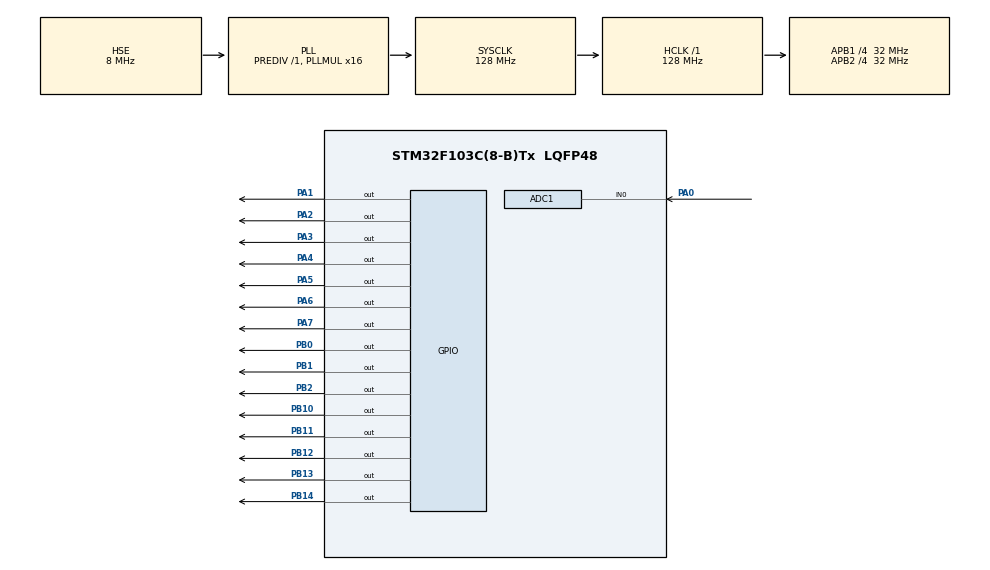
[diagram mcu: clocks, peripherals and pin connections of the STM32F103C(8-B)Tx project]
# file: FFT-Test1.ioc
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ADC1.Channel-7\#ChannelRegularConversion=ADC_CHANNEL_0
ADC1.ContinuousConvMode=DISABLE
ADC1.DataAlign=ADC_DATAALIGN_RIGHT
ADC1.DiscontinuousConvMode=DISABLE
ADC1.EnableAnalogWatchDog=false
ADC1.EnableRegularConversion=ENABLE
ADC1.ExternalTrigConv=ADC_SOFTWARE_START
ADC1.InjNumberOfConversion=0
ADC1.NbrOfConversion=1
ADC1.NbrOfConversionFlag=1
ADC1.Rank-7\#ChannelRegularConversion=1
ADC1.SamplingTime-7\#ChannelRegularConversion=ADC_SAMPLETIME_1CYCLE_5
ADC1.ScanConvMode=ADC_SCAN_DISABLE
ADC1.master=1
Mcu.Family=STM32F1
Mcu.Name=STM32F103C(8-B)Tx
Mcu.Package=LQFP48
NVIC.PriorityGroup=NVIC_PRIORITYGROUP_4
NVIC.TIM2_IRQn=true\:0\:0\:true\:false\:true\:true
NVIC.TIM4_IRQn=true\:1\:0\:true\:false\:true\:true
PA0-WKUP.Signal=ADCx_IN0
PA1.GPIO_ModeDefaultOutputPP=GPIO_MODE_OUTPUT_PP
PA1.GPIO_Speed=GPIO_SPEED_FREQ_HIGH
PA1.PinState=GPIO_PIN_SET
PA1.Signal=GPIO_Output
PA13.Mode=Serial_Wire
PA13.Signal=SYS_JTMS-SWDIO
PA14.Mode=Serial_Wire
PA14.Signal=SYS_JTCK-SWCLK
PA2.GPIO_ModeDefaultOutputPP=GPIO_MODE_OUTPUT_PP
PA2.GPIO_Speed=GPIO_SPEED_FREQ_HIGH
PA2.PinState=GPIO_PIN_SET
PA2.Signal=GPIO_Output
PA3.GPIO_ModeDefaultOutputPP=GPIO_MODE_OUTPUT_PP
PA3.GPIO_Speed=GPIO_SPEED_FREQ_HIGH
PA3.PinState=GPIO_PIN_SET
PA3.Signal=GPIO_Output
PA4.GPIO_ModeDefaultOutputPP=GPIO_MODE_OUTPUT_PP
PA4.GPIO_Speed=GPIO_SPEED_FREQ_HIGH
PA4.PinState=GPIO_PIN_SET
PA4.Signal=GPIO_Output
PA5.GPIO_ModeDefaultOutputPP=GPIO_MODE_OUTPUT_PP
PA5.GPIO_Speed=GPIO_SPEED_FREQ_HIGH
PA5.PinState=GPIO_PIN_SET
PA5.Signal=GPIO_Output
PA6.GPIO_ModeDefaultOutputPP=GPIO_MODE_OUTPUT_PP
PA6.GPIO_Speed=GPIO_SPEED_FREQ_HIGH
PA6.PinState=GPIO_PIN_SET
PA6.Signal=GPIO_Output
PA7.GPIO_ModeDefaultOutputPP=GPIO_MODE_OUTPUT_PP
PA7.GPIO_Speed=GPIO_SPEED_FREQ_HIGH
PA7.PinState=GPIO_PIN_SET
PA7.Signal=GPIO_Output
PB0.GPIO_ModeDefaultOutputPP=GPIO_MODE_OUTPUT_PP
PB0.GPIO_Speed=GPIO_SPEED_FREQ_HIGH
PB0.PinState=GPIO_PIN_SET
PB0.Signal=GPIO_Output
PB1.GPIO_ModeDefaultOutputPP=GPIO_MODE_OUTPUT_PP
PB1.GPIO_Speed=GPIO_SPEED_FREQ_HIGH
PB1.PinState=GPIO_PIN_SET
PB1.Signal=GPIO_Output
PB10.GPIO_ModeDefaultOutputPP=GPIO_MODE_OUTPUT_PP
PB10.GPIO_Speed=GPIO_SPEED_FREQ_HIGH
PB10.PinState=GPIO_PIN_SET
PB10.Signal=GPIO_Output
PB11.GPIO_Speed=GPIO_SPEED_FREQ_HIGH
PB11.PinState=GPIO_PIN_SET
PB11.Signal=GPIO_Output
PB12.GPIO_ModeDefaultOutputPP=GPIO_MODE_OUTPUT_PP
PB12.GPIO_Speed=GPIO_SPEED_FREQ_HIGH
PB12.PinState=GPIO_PIN_SET
PB12.Signal=GPIO_Output
PB13.GPIO_ModeDefaultOutputPP=GPIO_MODE_OUTPUT_PP
PB13.GPIO_Speed=GPIO_SPEED_FREQ_HIGH
PB13.PinState=GPIO_PIN_SET
PB13.Signal=GPIO_Output
PB14.GPIO_ModeDefaultOutputPP=GPIO_MODE_OUTPUT_PP
PB14.GPIO_Speed=GPIO_SPEED_FREQ_HIGH
PB14.PinState=GPIO_PIN_SET
PB14.Signal=GPIO_Output
PB2.GPIO_ModeDefaultOutputPP=GPIO_MODE_OUTPUT_PP
PB2.GPIO_Speed=GPIO_SPEED_FREQ_HIGH
PB2.PinState=GPIO_PIN_SET
PB2.Signal=GPIO_Output
PD0-OSC_IN.Mode=HSE-External-Oscillator
PD0-OSC_IN.Signal=RCC_OSC_IN
PD1-OSC_OUT.Mode=HSE-External-Oscillator
PD1-OSC_OUT.Signal=RCC_OSC_OUT
ProjectManager.HeapSize=0x200
ProjectManager.StackSize=0x400
ProjectManager.TargetToolchain=MDK-ARM V5
RCC.ADCPresc=RCC_ADCPCLK2_DIV4
RCC.AHBFreq_Value=128000000
RCC.APB1CLKDivider=RCC_HCLK_DIV4
RCC.APB1Freq_Value=32000000
RCC.APB1TimFreq_Value=64000000
RCC.APB2CLKDivider=RCC_HCLK_DIV4
RCC.APB2Freq_Value=32000000
RCC.APB2TimFreq_Value=64000000
RCC.HCLKFreq_Value=128000000
RCC.PLLMUL=RCC_PLL_MUL16
RCC.PLLSourceVirtual=RCC_PLLSOURCE_HSE
RCC.SYSCLKFreq_VALUE=128000000
RCC.SYSCLKSource=RCC_SYSCLKSOURCE_PLLCLK
RCC.USBFreq_Value=85333333.33333333
RCC.USBPrescaler=RCC_USBCLKSOURCE_PLL_DIV1_5
SH.ADCx_IN0.0=ADC1_IN0,IN0
TIM2.Period=1999
TIM2.Prescaler=32000
TIM3.Period=24
TIM3.Prescaler=64
TIM4.Period=33
TIM4.Prescaler=1152
VP_TIM2_VS_ClockSourceINT.Mode=Internal
VP_TIM3_VS_ClockSourceINT.Mode=Internal
VP_TIM4_VS_ClockSourceINT.Mode=Internal
board=FFT-Test1

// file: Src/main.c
#include "main.h"
#include "stm32f1xx_hal.h"

/* USER CODE BEGIN Includes */
#include <stdlib.h>
#include <math.h>
/* USER CODE END Includes */

ADC_HandleTypeDef hadc1;

TIM_HandleTypeDef htim2;
TIM_HandleTypeDef htim3;
TIM_HandleTypeDef htim4;

/* USER CODE BEGIN PV */
/* Private variables ---------------------------------------------------------*/

#define xuat      10 //B
#define OE        11 //B
#define clk       1  //A

#define A         0  //B
#define B         1  //B
#define C         13 //B
#define D         14 //B

#define B2        7
#define R2        6
#define G2        2

#define B1        5
#define R1        4
#define G1        3

#define OE_P       GPIOB
#define xuat_P     GPIOB
#define clk_P      GPIOA
#define A_P        GPIOB
#define B_P        GPIOB
#define C_P        GPIOB
#define D_P        GPIOB

const unsigned int timer_clock[5]={9,18,36,72,144}; // he so chia T4
//const unsigned int timer_clock[5]={9,18,36,72,144,288,575,1152};
unsigned char vitri_bit=0,row=0; // kiem tra xem dang quet den bit nao

signed char hang_led;
unsigned char display[3][32][64]={0};
unsigned int dem_ADC;

uint32_t t_show;

/* USER CODE END PV */

void SystemClock_Config(void);
static void MX_GPIO_Init(void);
static void MX_TIM2_Init(void);
static void MX_ADC1_Init(void);
static void MX_TIM4_Init(void);
static void MX_TIM3_Init(void);

/* USER CODE BEGIN PFP */
/* Private function prototypes -----------------------------------------------*/

#define N       512
#define log2N   9

int32_t RE[N];
int32_t IM[N];
int32_t data_M[64];
char data_MT[64];

// bang tra cuu Sin(a) cho FFT 512 diem
const signed char Sin_table[511] =
{
0,    // Temp_N = 2
0,-100,    // Temp_N = 4
0,-71,-100,-71,    // Temp_N = 8
0,-38,-71,-92,-100,-92,-71,-38,    // Temp_N = 16
0,-20,-38,-56,-71,-83,-92,-98,-100,-98,-92,-83,-71,-56,-38,-20,    // Temp_N = 32
0,-10,-20,-29,-38,-47,-56,-63,-71,-77,-83,-88,-92,-96,-98,-100,-100,-100,-98,-96,-92,-88,-83,-77,-71,-63,-56,-47,-38,-29,-20,-10,    // Temp_N = 64
0,-5,-10,-15,-20,-24,-29,-34,-38,-43,-47,-51,-56,-60,-63,-67,-71,-74,-77,-80,-83,-86,-88,-90,-92,-94,-96,-97,-98,-99,-100,-100,-100,-100,-100,-99,-98,-97,-96,-94,-92,-90,-88,-86,-83,-80,-77,-74,-71,-67,-63,-60,-56,-51,-47,-43,-38,-34,-29,-24,-20,-15,-10,-5,    // Temp_N = 128
0,-3,-5,-7,-10,-12,-15,-17,-20,-22,-24,-27,-29,-31,-34,-36,-38,-41,-43,-45,-47,-49,-51,-54,-56,-58,-60,-62,-63,-65,-67,-69,-71,-72,-74,-76,-77,-79,-80,-82,-83,-85,-86,-87,-88,-89,-90,-91,-92,-93,-94,-95,-96,-96,-97,-98,-98,-99,-99,-99,-100,-100,-100,-100,-100,-100,-100,-100,-100,-99,-99,-99,-98,-98,-97,-96,-96,-95,-94,-93,-92,-91,-90,-89,-88,-87,-86,-85,-83,-82,-80,-79,-77,-76,-74,-72,-71,-69,-67,-65,-63,-62,-60,-58,-56,-54,-51,-49,-47,-45,-43,-41,-38,-36,-34,-31,-29,-27,-24,-22,-20,-17,-15,-12,-10,-7,-5,-3,    // Temp_N = 256
0,-1,-3,-4,-5,-6,-7,-9,-10,-11,-12,-14,-15,-16,-17,-18,-20,-21,-22,-23,-24,-26,-27,-28,-29,-30,-31,-33,-34,-35,-36,-37,-38,-39,-41,-42,-43,-44,-45,-46,-47,-48,-49,-50,-51,-53,-54,-55,-56,-57,-58,-59,-60,-61,-62,-63,-63,-64,-65,-66,-67,-68,-69,-70,-71,-72,-72,-73,-74,-75,-76,-77,-77,-78,-79,-80,-80,-81,-82,-83,-83,-84,-85,-85,-86,-86,-87,-88,-88,-89,-89,-90,-90,-91,-91,-92,-92,-93,-93,-94,-94,-95,-95,-95,-96,-96,-96,-97,-97,-97,-98,-98,-98,-98,-99,-99,-99,-99,-99,-99,-100,-100,-100,-100,-100,-100,-100,-100,-100,-100,-100,-100,-100,-100,-100,-100,-100,-99,-99,-99,-99,-99,-99,-98,-98,-98,-98,-97,-97,-97,-96,-96,-96,-95,-95,-95,-94,-94,-93,-93,-92,-92,-91,-91,-90,-90,-89,-89,-88,-88,-87,-86,-86,-85,-85,-84,-83,-83,-82,-81,-80,-80,-79,-78,-77,-77,-76,-75,-74,-73,-72,-72,-71,-70,-69,-68,-67,-66,-65,-64,-63,-63,-62,-61,-60,-59,-58,-57,-56,-55,-54,-53,-51,-50,-49,-48,-47,-46,-45,-44,-43,-42,-41,-39,-38,-37,-36,-35,-34,-33,-31,-30,-29,-28,-27,-26,-24,-23,-22,-21,-20,-18,-17,-16,-15,-14,-12,-11,-10,-9,-7,-6,-5,-4,-3,-1,    // Temp_N = 512
};

// bang tra cuu Cos(a) cho FFT 512 diem
const signed char Cos_table[511] =
{
100,    // Temp_N = 2
100,0,    // Temp_N = 4
100,71,0,-71,    // Temp_N = 8
100,92,71,38,0,-38,-71,-92,    // Temp_N = 16
100,98,92,83,71,56,38,20,0,-20,-38,-56,-71,-83,-92,-98,    // Temp_N = 32
100,100,98,96,92,88,83,77,71,63,56,47,38,29,20,10,0,-10,-20,-29,-38,-47,-56,-63,-71,-77,-83,-88,-92,-96,-98,-100,    // Temp_N = 64
100,100,100,99,98,97,96,94,92,90,88,86,83,80,77,74,71,67,63,60,56,51,47,43,38,34,29,24,20,15,10,5,0,-5,-10,-15,-20,-24,-29,-34,-38,-43,-47,-51,-56,-60,-63,-67,-71,-74,-77,-80,-83,-86,-88,-90,-92,-94,-96,-97,-98,-99,-100,-100,    // Temp_N = 128
100,100,100,100,100,99,99,99,98,98,97,96,96,95,94,93,92,91,90,89,88,87,86,85,83,82,80,79,77,76,74,72,71,69,67,65,63,62,60,58,56,54,51,49,47,45,43,41,38,36,34,31,29,27,24,22,20,17,15,12,10,7,5,3,0,-3,-5,-7,-10,-12,-15,-17,-20,-22,-24,-27,-29,-31,-34,-36,-38,-41,-43,-45,-47,-49,-51,-54,-56,-58,-60,-62,-63,-65,-67,-69,-71,-72,-74,-76,-77,-79,-80,-82,-83,-85,-86,-87,-88,-89,-90,-91,-92,-93,-94,-95,-96,-96,-97,-98,-98,-99,-99,-99,-100,-100,-100,-100,    // Temp_N = 256
100,100,100,100,100,100,100,100,100,99,99,99,99,99,99,98,98,98,98,97,97,97,96,96,96,95,95,95,94,94,93,93,92,92,91,91,90,90,89,89,88,88,87,86,86,85,85,84,83,83,82,81,80,80,79,78,77,77,76,75,74,73,72,72,71,70,69,68,67,66,65,64,63,63,62,61,60,59,58,57,56,55,54,53,51,50,49,48,47,46,45,44,43,42,41,39,38,37,36,35,34,33,31,30,29,28,27,26,24,23,22,21,20,18,17,16,15,14,12,11,10,9,7,6,5,4,3,1,0,-1,-3,-4,-5,-6,-7,-9,-10,-11,-12,-14,-15,-16,-17,-18,-20,-21,-22,-23,-24,-26,-27,-28,-29,-30,-31,-33,-34,-35,-36,-37,-38,-39,-41,-42,-43,-44,-45,-46,-47,-48,-49,-50,-51,-53,-54,-55,-56,-57,-58,-59,-60,-61,-62,-63,-63,-64,-65,-66,-67,-68,-69,-70,-71,-72,-72,-73,-74,-75,-76,-77,-77,-78,-79,-80,-80,-81,-82,-83,-83,-84,-85,-85,-86,-86,-87,-88,-88,-89,-89,-90,-90,-91,-91,-92,-92,-93,-93,-94,-94,-95,-95,-95,-96,-96,-96,-97,-97,-97,-98,-98,-98,-98,-99,-99,-99,-99,-99,-99,-100,-100,-100,-100,-100,-100,-100,-100,    // Temp_N = 512
};
const unsigned char image[3][32][64]=
{
//[64x32]  (C) 2017 By Dao Nguyen
//Red
0x03,0x01,0x00,0x00,0x00,0x00,0x00,0x00,0x00,0x01,0x01,0x00,0x00,0x00,0x00,0x00,0x00,0x00,0x00,0x00,0x00,0x00,0x00,0x00,0x00,0x00,0x02,0x04,0x06,0x09,0x0D,0x10,0x13,0x16,0x1A,0x1C,0x1E,0x1F,0x1F,0x1E,0x1E,0x1E,0x1F,0x1F,0x1F,0x1F,0x1F,0x1F,0x1F,0x1F,0x1F,0x1F,0x1F,0x1F,0x1F,0x1F,0x1F,0x1F,0x1F,0x1F,0x1F,0x1F,0x1F,0x1F,
0x04,0x02,0x00,0x00,0x00,0x00,0x00,0x00,0x00,0x00,0x00,0x00,0x00,0x00,0x00,0x00,0x00,0x00,0x00,0x00,0x00,0x00,0x00,0x00,0x00,0x00,0x02,0x03,0x05,0x08,0x0C,0x0F,0x12,0x15,0x19,0x1B,0x1D,0x1F,0x1F,0x1F,0x1F,0x1F,0x1F,0x1F,0x1F,0x1F,0x1F,0x1F,0x1F,0x1F,0x1F,0x1F,0x1F,0x1F,0x1F,0x1F,0x1F,0x1F,0x1F,0x1F,0x1F,0x1F,0x1F,0x1F,
0x05,0x03,0x01,0x00,0x00,0x00,0x00,0x00,0x00,0x00,0x00,0x00,0x00,0x00,0x00,0x00,0x00,0x00,0x00,0x00,0x00,0x00,0x00,0x00,0x00,0x00,0x01,0x02,0x04,0x07,0x0B,0x0E,0x11,0x14,0x17,0x1A,0x1C,0x1E,0x1F,0x1F,0x1F,0x1F,0x1F,0x1F,0x1F,0x1F,0x1F,0x1F,0x1F,0x1F,0x1F,0x1F,0x1F,0x1F,0x1F,0x1F,0x1F,0x1F,0x1F,0x1F,0x1F,0x1F,0x1F,0x1F,
0x06,0x04,0x02,0x00,0x00,0x00,0x00,0x00,0x00,0x00,0x00,0x00,0x00,0x00,0x00,0x00,0x00,0x00,0x00,0x00,0x00,0x00,0x00,0x00,0x00,0x00,0x01,0x02,0x03,0x06,0x09,0x0D,0x0F,0x12,0x16,0x19,0x1C,0x1E,0x1F,0x1F,0x1F,0x1F,0x1F,0x1F,0x1F,0x1F,0x1F,0x1F,0x1F,0x1F,0x1F,0x1F,0x1F,0x1F,0x1F,0x1F,0x1F,0x1F,0x1F,0x1F,0x1F,0x1F,0x1F,0x1F,
0x08,0x05,0x02,0x01,0x00,0x00,0x00,0x00,0x00,0x00,0x01,0x00,0x00,0x00,0x00,0x00,0x00,0x00,0x00,0x00,0x00,0x00,0x00,0x00,0x00,0x00,0x00,0x01,0x02,0x04,0x08,0x0B,0x0E,0x11,0x15,0x18,0x1A,0x1D,0x1E,0x1F,0x1F,0x1F,0x1F,0x1F,0x1E,0x1E,0x1F,0x1F,0x1F,0x1E,0x1E,0x1F,0x1F,0x1F,0x1F,0x1F,0x1F,0x1F,0x1F,0x1F,0x1F,0x1F,0x1F,0x1F,
0x09,0x07,0x04,0x01,0x00,0x00,0x00,0x00,0x00,0x00,0x01,0x01,0x00,0x00,0x00,0x00,0x00,0x00,0x00,0x00,0x00,0x00,0x00,0x00,0x00,0x00,0x00,0x00,0x01,0x03,0x06,0x09,0x0C,0x0F,0x13,0x17,0x19,0x1C,0x1E,0x1F,0x1F,0x1F,0x1F,0x1F,0x1E,0x1E,0x1F,0x1F,0x1F,0x1E,0x1E,0x1F,0x1F,0x1F,0x1F,0x1F,0x1F,0x1F,0x1F,0x1F,0x1F,0x1F,0x1F,0x1F,
0x0A,0x08,0x04,0x02,0x01,0x00,0x00,0x00,0x00,0x00,0x00,0x00,0x00,0x00,0x00,0x00,0x00,0x00,0x00,0x00,0x00,0x00,0x00,0x00,0x00,0x00,0x00,0x00,0x00,0x02,0x05,0x08,0x0B,0x0E,0x12,0x16,0x18,0x1B,0x1D,0x1F,0x1F,0x1F,0x1F,0x1F,0x1E,0x1F,0x1F,0x1F,0x1F,0x1F,0x1E,0x1F,0x1F,0x1F,0x1F,0x1F,0x1F,0x1F,0x1F,0x1F,0x1F,0x1F,0x1F,0x1F,
0x0B,0x09,0x05,0x03,0x01,0x00,0x00,0x00,0x00,0x00,0x00,0x00,0x00,0x00,0x00,0x00,0x00,0x00,0x00,0x00,0x00,0x00,0x00,0x00,0x00,0x00,0x00,0x00,0x00,0x02,0x04,0x07,0x0A,0x0D,0x11,0x15,0x17,0x1A,0x1D,0x1F,0x1F,0x1F,0x1F,0x1F,0x1F,0x1F,0x1F,0x1F,0x1F,0x1F,0x1E,0x1F,0x1F,0x1F,0x1F,0x1F,0x1F,0x1F,0x1F,0x1F,0x1F,0x1F,0x1F,0x1F,
0x0D,0x0A,0x07,0x05,0x03,0x01,0x00,0x00,0x00,0x00,0x00,0x00,0x00,0x00,0x00,0x01,0x00,0x00,0x00,0x00,0x00,0x00,0x00,0x00,0x01,0x00,0x00,0x00,0x00,0x01,0x03,0x05,0x09,0x0B,0x0F,0x12,0x15,0x18,0x1B,0x1E,0x1E,0x1F,0x1F,0x1F,0x1F,0x1F,0x1F,0x1E,0x1F,0x1F,0x1F,0x1F,0x1F,0x1F,0x1F,0x1F,0x1F,0x1F,0x1F,0x1F,0x1F,0x1F,0x1F,0x1F,
0x0E,0x0B,0x08,0x05,0x03,0x01,0x00,0x00,0x00,0x00,0x00,0x00,0x00,0x00,0x00,0x01,0x00,0x00,0x00,0x00,0x00,0x00,0x00,0x00,0x01,0x00,0x00,0x00,0x00,0x01,0x03,0x04,0x08,0x0B,0x0E,0x11,0x14,0x17,0x1B,0x1D,0x1E,0x1F,0x1F,0x1F,0x1F,0x1F,0x1F,0x1F,0x1F,0x1F,0x1F,0x1F,0x1F,0x1F,0x1F,0x1F,0x1F,0x1F,0x1F,0x1F,0x1F,0x1F,0x1F,0x1F,
0x0F,0x0C,0x09,0x06,0x04,0x02,0x00,0x00,0x00,0x00,0x00,0x00,0x00,0x00,0x00,0x00,0x00,0x00,0x00,0x00,0x00,0x00,0x00,0x00,0x01,0x00,0x00,0x00,0x00,0x01,0x02,0x04,0x07,0x09,0x0D,0x10,0x13,0x16,0x19,0x1C,0x1E,0x1F,0x1F,0x1F,0x1F,0x1F,0x1F,0x1F,0x1F,0x1F,0x1F,0x1F,0x1F,0x1F,0x1F,0x1F,0x1F,0x1F,0x1F,0x1F,0x1F,0x1F,0x1F,0x1F,
0x11,0x0E,0x0A,0x08,0x05,0x03,0x00,0x00,0x00,0x00,0x00,0x00,0x00,0x00,0x00,0x00,0x00,0x00,0x01,0x00,0x00,0x00,0x00,0x00,0x00,0x00,0x00,0x00,0x00,0x00,0x01,0x02,0x05,0x08,0x0B,0x0F,0x11,0x15,0x18,0x1B,0x1D,0x1E,0x1F,0x1F,0x1F,0x1F,0x1F,0x1F,0x1F,0x1F,0x1F,0x1F,0x1F,0x1F,0x1F,0x1F,0x1F,0x1F,0x1F,0x1F,0x1F,0x1F,0x1F,0x1F,
0x12,0x0F,0x0C,0x09,0x06,0x04,0x01,0x00,0x00,0x00,0x00,0x00,0x00,0x00,0x00,0x00,0x00,0x01,0x01,0x00,0x00,0x00,0x00,0x00,0x00,0x00,0x00,0x00,0x00,0x00,0x01,0x01,0x04,0x07,0x0A,0x0D,0x10,0x13,0x17,0x19,0x1C,0x1E,0x1F,0x1F,0x1F,0x1F,0x1F,0x1F,0x1F,0x1F,0x1E,0x1F,0x1F,0x1F,0x1F,0x1F,0x1F,0x1F,0x1F,0x1F,0x1F,0x1F,0x1F,0x1F,
0x13,0x10,0x0D,0x0A,0x07,0x05,0x02,0x00,0x00,0x01,0x00,0x00,0x01,0x00,0x00,0x00,0x00,0x00,0x00,0x00,0x00,0x00,0x00,0x00,0x00,0x00,0x00,0x00,0x00,0x00,0x00,0x01,0x03,0x05,0x09,0x0C,0x0F,0x12,0x15,0x18,0x1B,0x1D,0x1F,0x1F,0x1F,0x1F,0x1F,0x1F,0x1F,0x1F,0x1F,0x1F,0x1F,0x1F,0x1F,0x1F,0x1F,0x1F,0x1F,0x1F,0x1F,0x1F,0x1F,0x1F,
0x15,0x12,0x0E,0x0B,0x09,0x06,0x03,0x01,0x00,0x00,0x00,0x00,0x00,0x00,0x00,0x00,0x00,0x00,0x00,0x00,0x00,0x00,0x00,0x00,0x00,0x00,0x00,0x00,0x00,0x00,0x00,0x00,0x01,0x04,0x07,0x0B,0x0D,0x11,0x14,0x17,0x1A,0x1C,0x1E,0x1F,0x1F,0x1F,0x1F,0x1F,0x1F,0x1F,0x1F,0x1F,0x1F,0x1F,0x1F,0x1F,0x1F,0x1F,0x1F,0x1F,0x1F,0x1F,0x1F,0x1F,
0x16,0x13,0x0F,0x0C,0x09,0x06,0x04,0x02,0x00,0x00,0x00,0x00,0x00,0x00,0x00,0x00,0x00,0x00,0x00,0x00,0x00,0x00,0x00,0x01,0x00,0x00,0x00,0x00,0x00,0x00,0x00,0x00,0x01,0x03,0x07,0x0A,0x0D,0x10,0x14,0x16,0x1A,0x1C,0x1E,0x1F,0x1F,0x1F,0x1F,0x1F,0x1F,0x1F,0x1F,0x1F,0x1F,0x1F,0x1F,0x1F,0x1F,0x1F,0x1F,0x1F,0x1F,0x1F,0x1F,0x1F,
0x17,0x15,0x11,0x0E,0x0B,0x08,0x05,0x03,0x01,0x00,0x00,0x00,0x00,0x00,0x00,0x00,0x00,0x00,0x01,0x00,0x00,0x00,0x00,0x00,0x00,0x00,0x00,0x00,0x00,0x00,0x00,0x00,0x00,0x02,0x05,0x08,0x0A,0x0D,0x11,0x15,0x18,0x1A,0x1D,0x1E,0x1F,0x1F,0x1F,0x1F,0x1E,0x1F,0x1F,0x1F,0x1F,0x1E,0x1F,0x1F,0x1F,0x1F,0x1F,0x1F,0x1F,0x1F,0x1F,0x1F,
0x18,0x15,0x12,0x0F,0x0C,0x09,0x06,0x03,0x02,0x01,0x00,0x00,0x00,0x00,0x00,0x00,0x00,0x00,0x00,0x00,0x00,0x00,0x00,0x00,0x00,0x00,0x00,0x00,0x00,0x00,0x00,0x00,0x00,0x02,0x04,0x07,0x0A,0x0D,0x11,0x14,0x17,0x1A,0x1C,0x1E,0x1F,0x1F,0x1F,0x1F,0x1F,0x1F,0x1F,0x1F,0x1F,0x1F,0x1F,0x1F,0x1F,0x1F,0x1F,0x1F,0x1F,0x1F,0x1F,0x1F,
0x19,0x16,0x13,0x10,0x0D,0x0A,0x07,0x04,0x02,0x01,0x00,0x00,0x00,0x00,0x00,0x00,0x00,0x00,0x00,0x00,0x00,0x00,0x00,0x00,0x00,0x00,0x00,0x00,0x00,0x00,0x00,0x00,0x00,0x01,0x03,0x06,0x08,0x0B,0x0F,0x12,0x16,0x18,0x1B,0x1D,0x1F,0x1F,0x1F,0x1F,0x1F,0x1F,0x1F,0x1F,0x1F,0x1F,0x1F,0x1F,0x1F,0x1F,0x1F,0x1F,0x1F,0x1F,0x1F,0x1F,
0x1A,0x18,0x14,0x11,0x0F,0x0B,0x08,0x06,0x03,0x01,0x00,0x00,0x00,0x00,0x00,0x00,0x00,0x00,0x00,0x00,0x00,0x00,0x00,0x00,0x00,0x00,0x00,0x00,0x00,0x00,0x00,0x00,0x00,0x01,0x03,0x04,0x07,0x0A,0x0E,0x11,0x14,0x17,0x1A,0x1C,0x1E,0x1F,0x1F,0x1F,0x1F,0x1F,0x1F,0x1F,0x1F,0x1F,0x1F,0x1F,0x1F,0x1F,0x1F,0x1F,0x1F,0x1F,0x1F,0x1F,
0x1B,0x19,0x16,0x13,0x10,0x0D,0x09,0x07,0x04,0x02,0x00,0x00,0x00,0x00,0x00,0x00,0x00,0x00,0x00,0x00,0x00,0x00,0x00,0x00,0x00,0x00,0x00,0x00,0x00,0x00,0x00,0x00,0x00,0x01,0x02,0x03,0x05,0x08,0x0C,0x0F,0x13,0x15,0x19,0x1B,0x1D,0x1F,0x1F,0x1F,0x1F,0x1F,0x1F,0x1F,0x1F,0x1E,0x1E,0x1F,0x1F,0x1F,0x1F,0x1F,0x1F,0x1F,0x1F,0x1F,
0x1D,0x1A,0x17,0x14,0x12,0x0E,0x0B,0x08,0x05,0x03,0x01,0x00,0x00,0x00,0x00,0x00,0x00,0x00,0x01,0x00,0x00,0x00,0x00,0x00,0x00,0x00,0x00,0x00,0x00,0x00,0x00,0x00,0x00,0x00,0x01,0x02,0x04,0x06,0x0B,0x0E,0x11,0x14,0x17,0x1B,0x1D,0x1E,0x1F,0x1F,0x1F,0x1F,0x1F,0x1F,0x1F,0x1E,0x1F,0x1F,0x1F,0x1F,0x1F,0x1F,0x1F,0x1F,0x1F,0x1F,
0x1E,0x1B,0x18,0x15,0x12,0x0F,0x0C,0x09,0x06,0x04,0x02,0x01,0x00,0x00,0x00,0x00,0x00,0x00,0x00,0x00,0x00,0x00,0x00,0x00,0x00,0x00,0x00,0x00,0x00,0x00,0x00,0x00,0x00,0x00,0x00,0x01,0x03,0x05,0x09,0x0C,0x10,0x13,0x16,0x1A,0x1C,0x1D,0x1F,0x1F,0x1F,0x1F,0x1F,0x1F,0x1F,0x1F,0x1F,0x1F,0x1F,0x1F,0x1F,0x1F,0x1F,0x1F,0x1F,0x1F,
0x1F,0x1C,0x19,0x16,0x13,0x10,0x0D,0x0A,0x06,0x04,0x02,0x01,0x00,0x00,0x00,0x00,0x00,0x00,0x00,0x00,0x00,0x00,0x00,0x00,0x00,0x00,0x00,0x00,0x00,0x00,0x00,0x00,0x01,0x00,0x00,0x00,0x02,0x04,0x08,0x0C,0x0F,0x12,0x16,0x19,0x1B,0x1D,0x1F,0x1F,0x1F,0x1F,0x1F,0x1F,0x1F,0x1F,0x1F,0x1F,0x1F,0x1F,0x1F,0x1F,0x1F,0x1F,0x1F,0x1F,
0x1F,0x1D,0x1B,0x18,0x16,0x13,0x0F,0x0C,0x09,0x06,0x03,0x01,0x00,0x00,0x00,0x00,0x01,0x00,0x00,0x00,0x00,0x00,0x00,0x01,0x00,0x00,0x00,0x00,0x00,0x00,0x00,0x00,0x00,0x00,0x00,0x00,0x01,0x03,0x07,0x0A,0x0D,0x10,0x14,0x17,0x19,0x1B,0x1E,0x1F,0x1F,0x1F,0x1F,0x1F,0x1E,0x1E,0x1F,0x1F,0x1F,0x1F,0x1F,0x1F,0x1F,0x1F,0x1F,0x1F,
0x1F,0x1D,0x1B,0x19,0x16,0x14,0x10,0x0C,0x0A,0x07,0x04,0x02,0x00,0x00,0x00,0x00,0x00,0x00,0x00,0x00,0x00,0x00,0x00,0x01,0x00,0x00,0x00,0x00,0x00,0x00,0x00,0x00,0x00,0x00,0x00,0x00,0x01,0x03,0x06,0x09,0x0C,0x0F,0x13,0x16,0x18,0x1B,0x1D,0x1F,0x1F,0x1F,0x1F,0x1F,0x1F,0x1F,0x1F,0x1F,0x1F,0x1F,0x1F,0x1F,0x1F,0x1F,0x1F,0x1F,
0x1F,0x1E,0x1C,0x1A,0x18,0x15,0x11,0x0E,0x0B,0x08,0x05,0x03,0x01,0x00,0x00,0x00,0x00,0x00,0x00,0x00,0x00,0x00,0x00,0x00,0x00,0x00,0x00,0x00,0x00,0x00,0x00,0x00,0x00,0x00,0x00,0x00,0x00,0x02,0x05,0x08,0x0B,0x0D,0x11,0x15,0x17,0x1A,0x1D,0x1F,0x1F,0x1F,0x1F,0x1F,0x1F,0x1F,0x1F,0x1F,0x1F,0x1F,0x1F,0x1F,0x1F,0x1F,0x1F,0x1F,
0x1F,0x1E,0x1D,0x1B,0x19,0x16,0x12,0x0F,0x0C,0x09,0x06,0x04,0x02,0x00,0x00,0x00,0x00,0x00,0x00,0x00,0x00,0x00,0x00,0x00,0x00,0x00,0x00,0x00,0x00,0x00,0x00,0x00,0x00,0x00,0x00,0x00,0x00,0x01,0x04,0x06,0x09,0x0C,0x10,0x13,0x16,0x19,0x1C,0x1E,0x1F,0x1F,0x1F,0x1F,0x1F,0x1F,0x1F,0x1F,0x1F,0x1F,0x1F,0x1F,0x1F,0x1F,0x1F,0x1F,
0x1F,0x1F,0x1D,0x1C,0x1A,0x17,0x14,0x11,0x0D,0x0B,0x08,0x05,0x03,0x01,0x00,0x00,0x00,0x00,0x00,0x00,0x00,0x00,0x00,0x00,0x00,0x00,0x00,0x00,0x00,0x00,0x00,0x00,0x00,0x00,0x00,0x00,0x00,0x01,0x03,0x05,0x08,0x0A,0x0E,0x12,0x15,0x17,0x1A,0x1D,0x1E,0x1F,0x1F,0x1F,0x1F,0x1F,0x1F,0x1F,0x1F,0x1F,0x1F,0x1F,0x1F,0x1F,0x1F,0x1F,
0x1F,0x1F,0x1E,0x1C,0x1B,0x18,0x15,0x12,0x0F,0x0C,0x09,0x06,0x04,0x02,0x00,0x00,0x00,0x00,0x00,0x00,0x00,0x00,0x00,0x00,0x00,0x00,0x00,0x00,0x00,0x00,0x00,0x00,0x00,0x00,0x00,0x00,0x00,0x00,0x02,0x04,0x06,0x09,0x0D,0x10,0x13,0x16,0x1A,0x1C,0x1E,0x1F,0x1F,0x1F,0x1F,0x1F,0x1F,0x1E,0x1F,0x1F,0x1F,0x1F,0x1F,0x1F,0x1F,0x1F,
0x1F,0x1F,0x1E,0x1D,0x1C,0x1A,0x16,0x14,0x10,0x0D,0x0A,0x07,0x05,0x03,0x01,0x00,0x00,0x00,0x00,0x00,0x00,0x00,0x00,0x00,0x00,0x00,0x00,0x00,0x00,0x00,0x00,0x00,0x00,0x00,0x00,0x00,0x00,0x00,0x01,0x03,0x05,0x08,0x0C,0x0F,0x12,0x15,0x18,0x1B,0x1D,0x1E,0x1F,0x1F,0x1F,0x1F,0x1F,0x1F,0x1F,0x1F,0x1F,0x1F,0x1F,0x1F,0x1F,0x1F,
0x1F,0x1F,0x1F,0x1E,0x1C,0x1A,0x17,0x14,0x11,0x0E,0x0B,0x08,0x05,0x03,0x01,0x00,0x00,0x00,0x00,0x00,0x00,0x00,0x00,0x00,0x00,0x00,0x00,0x00,0x00,0x00,0x00,0x00,0x00,0x00,0x00,0x00,0x00,0x00,0x01,0x02,0x04,0x07,0x0B,0x0E,0x11,0x14,0x18,0x1A,0x1C,0x1E,0x1F,0x1F,0x1F,0x1F,0x1F,0x1F,0x1F,0x1F,0x1F,0x1F,0x1F,0x1F,0x1F,0x1F,
//Green
0x00,0x00,0x00,0x01,0x04,0x07,0x0B,0x0D,0x12,0x15,0x18,0x1B,0x1D,0x1F,0x1F,0x1F,0x1F,0x1F,0x1F,0x1F,0x1F,0x1F,0x1F,0x1F,0x1F,0x1F,0x1F,0x1F,0x1F,0x1F,0x1F,0x1F,0x1F,0x1F,0x1F,0x1F,0x1F,0x1F,0x1D,0x1A,0x17,0x13,0x10,0x0C,0x09,0x06,0x03,0x00,0x00,0x00,0x00,0x00,0x00,0x00,0x00,0x00,0x00,0x00,0x00,0x00,0x00,0x00,0x00,0x00,
0x00,0x00,0x00,0x01,0x03,0x06,0x0A,0x0D,0x11,0x14,0x17,0x1A,0x1D,0x1F,0x1F,0x1F,0x1F,0x1F,0x1F,0x1F,0x1F,0x1F,0x1F,0x1F,0x1F,0x1F,0x1F,0x1F,0x1F,0x1F,0x1F,0x1F,0x1F,0x1F,0x1F,0x1F,0x1F,0x1F,0x1D,0x1B,0x18,0x14,0x11,0x0D,0x0A,0x07,0x04,0x01,0x00,0x00,0x00,0x00,0x00,0x00,0x00,0x00,0x00,0x00,0x00,0x00,0x00,0x00,0x00,0x00,
0x00,0x00,0x00,0x01,0x02,0x05,0x09,0x0B,0x0F,0x12,0x16,0x19,0x1C,0x1E,0x1F,0x1F,0x1F,0x1F,0x1F,0x1F,0x1F,0x1F,0x1F,0x1F,0x1F,0x1F,0x1F,0x1F,0x1F,0x1F,0x1F,0x1F,0x1F,0x1F,0x1F,0x1F,0x1F,0x1F,0x1E,0x1C,0x19,0x16,0x12,0x0F,0x0B,0x08,0x05,0x02,0x00,0x00,0x00,0x00,0x00,0x00,0x00,0x00,0x00,0x00,0x00,0x00,0x00,0x00,0x00,0x00,
0x00,0x00,0x00,0x00,0x02,0x04,0x07,0x0A,0x0E,0x11,0x14,0x18,0x1B,0x1D,0x1F,0x1F,0x1F,0x1F,0x1F,0x1F,0x1F,0x1F,0x1F,0x1F,0x1F,0x1F,0x1F,0x1F,0x1F,0x1F,0x1F,0x1F,0x1F,0x1F,0x1F,0x1F,0x1F,0x1F,0x1E,0x1D,0x1A,0x17,0x14,0x10,0x0D,0x0A,0x06,0x03,0x01,0x00,0x00,0x00,0x00,0x00,0x00,0x00,0x00,0x00,0x00,0x00,0x00,0x00,0x00,0x00,
0x00,0x00,0x00,0x00,0x01,0x03,0x06,0x08,0x0D,0x0F,0x13,0x16,0x19,0x1C,0x1E,0x1F,0x1F,0x1F,0x1F,0x1F,0x1F,0x1F,0x1F,0x1F,0x1F,0x1F,0x1F,0x1F,0x1F,0x1F,0x1F,0x1F,0x1F,0x1F,0x1F,0x1F,0x1F,0x1F,0x1F,0x1E,0x1B,0x18,0x15,0x12,0x0E,0x0B,0x08,0x04,0x02,0x01,0x00,0x00,0x00,0x00,0x00,0x00,0x00,0x00,0x00,0x00,0x00,0x00,0x00,0x00,
0x00,0x00,0x00,0x00,0x00,0x02,0x04,0x07,0x0B,0x0E,0x11,0x15,0x18,0x1B,0x1D,0x1F,0x1F,0x1F,0x1F,0x1F,0x1F,0x1F,0x1F,0x1F,0x1F,0x1F,0x1F,0x1F,0x1F,0x1F,0x1F,0x1F,0x1F,0x1F,0x1F,0x1F,0x1F,0x1F,0x1F,0x1E,0x1D,0x1A,0x16,0x13,0x10,0x0D,0x09,0x06,0x03,0x02,0x00,0x00,0x00,0x00,0x00,0x00,0x00,0x00,0x00,0x00,0x00,0x00,0x00,0x00,
0x00,0x00,0x00,0x00,0x00,0x01,0x03,0x05,0x09,0x0C,0x10,0x14,0x17,0x1A,0x1D,0x1E,0x1F,0x1F,0x1F,0x1F,0x1F,0x1F,0x1F,0x1F,0x1F,0x1F,0x1F,0x1F,0x1F,0x1F,0x1F,0x1F,0x1F,0x1F,0x1F,0x1F,0x1F,0x1F,0x1F,0x1F,0x1E,0x1B,0x18,0x15,0x12,0x0E,0x0A,0x07,0x04,0x02,0x00,0x00,0x00,0x00,0x00,0x01,0x00,0x00,0x00,0x00,0x00,0x00,0x00,0x00,
0x00,0x00,0x00,0x00,0x00,0x01,0x03,0x04,0x08,0x0B,0x0F,0x12,0x16,0x19,0x1C,0x1E,0x1F,0x1F,0x1F,0x1F,0x1F,0x1F,0x1F,0x1F,0x1F,0x1F,0x1F,0x1F,0x1F,0x1F,0x1F,0x1F,0x1F,0x1F,0x1F,0x1F,0x1F,0x1F,0x1F,0x1F,0x1E,0x1C,0x19,0x16,0x13,0x0F,0x0B,0x08,0x04,0x02,0x00,0x00,0x00,0x00,0x00,0x01,0x00,0x00,0x00,0x00,0x00,0x00,0x00,0x00,
0x00,0x00,0x00,0x00,0x00,0x00,0x01,0x03,0x06,0x09,0x0D,0x11,0x14,0x17,0x1A,0x1D,0x1F,0x1F,0x1F,0x1F,0x1F,0x1F,0x1F,0x1F,0x1E,0x1F,0x1F,0x1F,0x1F,0x1F,0x1F,0x1F,0x1F,0x1F,0x1F,0x1F,0x1F,0x1F,0x1F,0x1F,0x1F,0x1E,0x1B,0x18,0x15,0x11,0x0D,0x0A,0x06,0x04,0x01,0x00,0x00,0x00,0x00,0x00,0x00,0x00,0x00,0x00,0x00,0x00,0x00,0x00,
0x00,0x00,0x00,0x00,0x00,0x00,0x01,0x03,0x05,0x08,0x0C,0x0F,0x13,0x16,0x19,0x1C,0x1E,0x1F,0x1F,0x1F,0x1F,0x1F,0x1F,0x1F,0x1F,0x1F,0x1F,0x1F,0x1F,0x1E,0x1F,0x1F,0x1F,0x1F,0x1F,0x1F,0x1F,0x1F,0x1F,0x1F,0x1F,0x1E,0x1B,0x18,0x15,0x12,0x0E,0x0B,0x07,0x05,0x02,0x00,0x00,0x00,0x00,0x00,0x00,0x00,0x00,0x00,0x00,0x00,0x00,0x00,
0x00,0x00,0x00,0x00,0x00,0x00,0x01,0x02,0x04,0x07,0x0B,0x0E,0x11,0x15,0x18,0x1B,0x1E,0x1F,0x1F,0x1F,0x1F,0x1F,0x1F,0x1F,0x1F,0x1F,0x1F,0x1F,0x1F,0x1E,0x1F,0x1F,0x1F,0x1F,0x1F,0x1F,0x1F,0x1F,0x1F,0x1F,0x1F,0x1E,0x1C,0x1A,0x17,0x13,0x10,0x0D,0x09,0x06,0x03,0x01,0x00,0x00,0x00,0x00,0x00,0x00,0x00,0x00,0x00,0x00,0x00,0x00,
0x00,0x00,0x00,0x00,0x00,0x00,0x00,0x01,0x03,0x06,0x09,0x0C,0x10,0x13,0x17,0x1A,0x1D,0x1E,0x1F,0x1F,0x1F,0x1F,0x1F,0x1F,0x1F,0x1F,0x1F,0x1F,0x1F,0x1E,0x1F,0x1F,0x1F,0x1F,0x1F,0x1F,0x1F,0x1F,0x1F,0x1F,0x1F,0x1F,0x1D,0x1B,0x18,0x15,0x11,0x0E,0x0A,0x08,0x04,0x02,0x00,0x00,0x00,0x00,0x00,0x00,0x00,0x00,0x00,0x00,0x00,0x00,
0x00,0x00,0x00,0x00,0x00,0x00,0x00,0x01,0x02,0x05,0x08,0x0B,0x0E,0x12,0x15,0x19,0x1B,0x1D,0x1F,0x1F,0x1F,0x1F,0x1F,0x1F,0x1F,0x1F,0x1F,0x1F,0x1F,0x1E,0x1F,0x1F,0x1F,0x1F,0x1F,0x1F,0x1F,0x1F,0x1F,0x1F,0x1F,0x1F,0x1E,0x1C,0x1A,0x16,0x12,0x10,0x0B,0x09,0x06,0x03,0x01,0x00,0x00,0x00,0x00,0x00,0x00,0x00,0x00,0x00,0x00,0x00,
0x00,0x00,0x00,0x00,0x00,0x00,0x00,0x00,0x01,0x04,0x06,0x09,0x0D,0x10,0x14,0x17,0x1A,0x1C,0x1E,0x1F,0x1F,0x1F,0x1F,0x1F,0x1F,0x1F,0x1F,0x1F,0x1F,0x1F,0x1F,0x1F,0x1F,0x1F,0x1F,0x1F,0x1F,0x1F,0x1F,0x1F,0x1F,0x1F,0x1F,0x1D,0x1B,0x18,0x14,0x11,0x0D,0x0A,0x07,0x04,0x01,0x00,0x00,0x00,0x00,0x00,0x00,0x00,0x00,0x00,0x00,0x00,
0x00,0x00,0x00,0x00,0x00,0x00,0x00,0x00,0x00,0x02,0x05,0x08,0x0B,0x0E,0x12,0x16,0x19,0x1B,0x1E,0x1F,0x1F,0x1F,0x1F,0x1F,0x1F,0x1F,0x1F,0x1F,0x1F,0x1F,0x1F,0x1F,0x1F,0x1F,0x1F,0x1F,0x1F,0x1F,0x1F,0x1F,0x1F,0x1F,0x1F,0x1E,0x1C,0x19,0x16,0x13,0x0E,0x0C,0x08,0x05,0x02,0x00,0x00,0x00,0x00,0x00,0x00,0x00,0x00,0x00,0x00,0x00,
0x00,0x00,0x00,0x00,0x00,0x00,0x00,0x00,0x00,0x02,0x04,0x07,0x0A,0x0D,0x11,0x15,0x18,0x1B,0x1D,0x1F,0x1F,0x1F,0x1F,0x1F,0x1F,0x1F,0x1F,0x1F,0x1F,0x1F,0x1F,0x1F,0x1F,0x1F,0x1F,0x1F,0x1F,0x1F,0x1F,0x1F,0x1F,0x1F,0x1F,0x1E,0x1D,0x1A,0x16,0x14,0x0F,0x0D,0x09,0x06,0x03,0x01,0x00,0x00,0x00,0x00,0x00,0x00,0x00,0x00,0x00,0x00,
0x00,0x00,0x00,0x00,0x00,0x00,0x00,0x00,0x00,0x01,0x03,0x05,0x08,0x0C,0x0F,0x12,0x16,0x19,0x1C,0x1E,0x1F,0x1F,0x1F,0x1F,0x1F,0x1F,0x1F,0x1F,0x1F,0x1F,0x1F,0x1F,0x1F,0x1F,0x1F,0x1F,0x1F,0x1F,0x1F,0x1F,0x1F,0x1F,0x1F,0x1F,0x1E,0x1C,0x18,0x16,0x12,0x0F,0x0B,0x07,0x04,0x02,0x00,0x00,0x00,0x00,0x00,0x00,0x00,0x00,0x00,0x00,
0x00,0x00,0x00,0x00,0x00,0x00,0x00,0x00,0x00,0x00,0x02,0x05,0x07,0x0B,0x0E,0x11,0x16,0x18,0x1B,0x1D,0x1F,0x1F,0x1F,0x1F,0x1F,0x1F,0x1F,0x1F,0x1F,0x1F,0x1F,0x1F,0x1F,0x1F,0x1F,0x1F,0x1F,0x1F,0x1F,0x1F,0x1F,0x1F,0x1F,0x1F,0x1E,0x1C,0x19,0x16,0x13,0x10,0x0C,0x08,0x05,0x03,0x01,0x00,0x00,0x00,0x00,0x00,0x00,0x00,0x00,0x00,
0x00,0x00,0x00,0x00,0x00,0x00,0x00,0x00,0x00,0x00,0x01,0x03,0x06,0x09,0x0D,0x10,0x14,0x17,0x1A,0x1C,0x1E,0x1F,0x1F,0x1F,0x1F,0x1F,0x1F,0x1F,0x1F,0x1F,0x1F,0x1F,0x1F,0x1F,0x1F,0x1F,0x1F,0x1F,0x1F,0x1F,0x1F,0x1F,0x1F,0x1F,0x1F,0x1D,0x1A,0x18,0x14,0x11,0x0D,0x0A,0x07,0x04,0x02,0x00,0x00,0x00,0x00,0x00,0x00,0x00,0x00,0x00,
0x00,0x00,0x00,0x00,0x00,0x00,0x00,0x00,0x00,0x00,0x01,0x02,0x05,0x08,0x0C,0x0E,0x13,0x15,0x19,0x1C,0x1E,0x1F,0x1F,0x1F,0x1F,0x1F,0x1F,0x1F,0x1F,0x1F,0x1F,0x1F,0x1F,0x1F,0x1F,0x1F,0x1F,0x1F,0x1F,0x1F,0x1F,0x1F,0x1F,0x1F,0x1F,0x1E,0x1C,0x19,0x16,0x13,0x0F,0x0B,0x08,0x05,0x02,0x01,0x00,0x00,0x00,0x00,0x00,0x00,0x00,0x00,
0x00,0x00,0x00,0x00,0x00,0x00,0x00,0x00,0x00,0x00,0x00,0x01,0x03,0x06,0x0A,0x0D,0x11,0x14,0x17,0x1B,0x1D,0x1F,0x1F,0x1F,0x1F,0x1F,0x1F,0x1F,0x1F,0x1F,0x1F,0x1F,0x1F,0x1F,0x1F,0x1F,0x1F,0x1F,0x1F,0x1F,0x1F,0x1F,0x1F,0x1F,0x1F,0x1F,0x1D,0x1B,0x17,0x14,0x10,0x0D,0x0A,0x06,0x03,0x02,0x00,0x00,0x00,0x00,0x00,0x00,0x00,0x00,
0x00,0x00,0x00,0x00,0x00,0x00,0x00,0x00,0x00,0x00,0x00,0x01,0x02,0x05,0x09,0x0C,0x0F,0x12,0x16,0x19,0x1C,0x1E,0x1F,0x1F,0x1F,0x1F,0x1F,0x1F,0x1F,0x1F,0x1F,0x1F,0x1F,0x1F,0x1F,0x1F,0x1F,0x1F,0x1F,0x1F,0x1F,0x1F,0x1F,0x1F,0x1F,0x1F,0x1D,0x1C,0x19,0x16,0x12,0x0F,0x0B,0x08,0x04,0x02,0x00,0x00,0x00,0x00,0x00,0x00,0x00,0x00,
0x00,0x00,0x00,0x00,0x00,0x00,0x00,0x00,0x00,0x00,0x00,0x00,0x01,0x04,0x07,0x0A,0x0E,0x11,0x15,0x18,0x1B,0x1D,0x1F,0x1F,0x1F,0x1F,0x1F,0x1F,0x1F,0x1F,0x1F,0x1F,0x1F,0x1F,0x1F,0x1F,0x1F,0x1F,0x1F,0x1F,0x1F,0x1F,0x1F,0x1F,0x1F,0x1F,0x1E,0x1D,0x1A,0x17,0x13,0x10,0x0D,0x09,0x05,0x03,0x00,0x00,0x00,0x00,0x00,0x00,0x00,0x00,
0x00,0x00,0x00,0x00,0x00,0x00,0x00,0x00,0x00,0x00,0x00,0x00,0x01,0x03,0x06,0x09,0x0D,0x10,0x14,0x17,0x1A,0x1D,0x1E,0x1F,0x1F,0x1F,0x1F,0x1F,0x1F,0x1F,0x1F,0x1F,0x1F,0x1F,0x1F,0x1F,0x1F,0x1F,0x1F,0x1F,0x1F,0x1F,0x1F,0x1F,0x1F,0x1F,0x1F,0x1E,0x1B,0x18,0x14,0x11,0x0E,0x0A,0x06,0x04,0x01,0x00,0x00,0x00,0x00,0x00,0x00,0x00,
0x00,0x00,0x00,0x00,0x00,0x00,0x00,0x00,0x00,0x00,0x00,0x00,0x00,0x02,0x04,0x07,0x0A,0x0E,0x12,0x16,0x19,0x1B,0x1D,0x1F,0x1F,0x1F,0x1F,0x1F,0x1F,0x1F,0x1F,0x1F,0x1F,0x1F,0x1F,0x1F,0x1F,0x1F,0x1F,0x1F,0x1F,0x1F,0x1F,0x1F,0x1F,0x1F,0x1F,0x1F,0x1C,0x1A,0x16,0x13,0x10,0x0C,0x08,0x06,0x02,0x01,0x00,0x00,0x00,0x00,0x00,0x00,
0x00,0x00,0x00,0x00,0x00,0x00,0x00,0x00,0x00,0x00,0x00,0x00,0x00,0x01,0x04,0x06,0x09,0x0D,0x11,0x15,0x18,0x1A,0x1D,0x1F,0x1F,0x1F,0x1F,0x1F,0x1F,0x1F,0x1F,0x1F,0x1F,0x1F,0x1F,0x1F,0x1F,0x1F,0x1F,0x1F,0x1F,0x1F,0x1F,0x1F,0x1F,0x1F,0x1F,0x1F,0x1D,0x1A,0x17,0x14,0x11,0x0D,0x09,0x07,0x03,0x02,0x00,0x00,0x00,0x00,0x00,0x00,
0x00,0x00,0x00,0x00,0x00,0x00,0x00,0x00,0x00,0x00,0x00,0x00,0x00,0x01,0x03,0x05,0x08,0x0B,0x0F,0x13,0x16,0x19,0x1C,0x1E,0x1F,0x1F,0x1F,0x1F,0x1F,0x1F,0x1F,0x1F,0x1F,0x1F,0x1F,0x1F,0x1F,0x1F,0x1F,0x1F,0x1F,0x1F,0x1F,0x1F,0x1F,0x1F,0x1F,0x1F,0x1E,0x1C,0x18,0x15,0x12,0x0F,0x0B,0x08,0x04,0x03,0x01,0x00,0x00,0x00,0x00,0x00,
0x00,0x00,0x00,0x00,0x00,0x00,0x00,0x00,0x00,0x00,0x00,0x00,0x00,0x00,0x02,0x04,0x07,0x0A,0x0E,0x11,0x15,0x18,0x1B,0x1D,0x1F,0x1F,0x1F,0x1F,0x1F,0x1F,0x1F,0x1F,0x1F,0x1F,0x1F,0x1F,0x1F,0x1F,0x1F,0x1F,0x1F,0x1F,0x1F,0x1F,0x1F,0x1F,0x1F,0x1F,0x1F,0x1D,0x1A,0x17,0x14,0x10,0x0C,0x0A,0x06,0x04,0x01,0x00,0x00,0x00,0x00,0x00,
0x00,0x00,0x00,0x00,0x00,0x00,0x00,0x00,0x00,0x00,0x00,0x00,0x00,0x00,0x01,0x03,0x05,0x09,0x0C,0x10,0x13,0x16,0x1A,0x1D,0x1E,0x1F,0x1F,0x1F,0x1F,0x1F,0x1F,0x1F,0x1F,0x1F,0x1F,0x1F,0x1F,0x1F,0x1F,0x1F,0x1F,0x1F,0x1F,0x1F,0x1F,0x1F,0x1F,0x1F,0x1F,0x1E,0x1B,0x18,0x15,0x12,0x0E,0x0B,0x07,0x05,0x02,0x01,0x00,0x00,0x00,0x00,
0x00,0x00,0x00,0x00,0x00,0x00,0x00,0x00,0x00,0x00,0x00,0x00,0x00,0x00,0x01,0x02,0x04,0x07,0x0B,0x0E,0x12,0x15,0x18,0x1C,0x1D,0x1F,0x1F,0x1F,0x1F,0x1F,0x1F,0x1F,0x1F,0x1F,0x1F,0x1F,0x1F,0x1F,0x1F,0x1F,0x1F,0x1F,0x1F,0x1F,0x1F,0x1F,0x1F,0x1F,0x1F,0x1E,0x1C,0x19,0x17,0x13,0x0F,0x0C,0x09,0x06,0x03,0x01,0x00,0x00,0x00,0x00,
0x00,0x00,0x00,0x00,0x00,0x00,0x00,0x00,0x00,0x00,0x00,0x00,0x00,0x00,0x00,0x01,0x03,0x06,0x09,0x0D,0x10,0x14,0x17,0x1A,0x1D,0x1E,0x1F,0x1F,0x1F,0x1F,0x1F,0x1F,0x1F,0x1F,0x1F,0x1F,0x1F,0x1F,0x1F,0x1F,0x1F,0x1F,0x1F,0x1F,0x1F,0x1F,0x1F,0x1F,0x1F,0x1F,0x1D,0x1B,0x18,0x15,0x11,0x0E,0x0A,0x07,0x04,0x01,0x00,0x00,0x00,0x00,
0x00,0x00,0x00,0x00,0x00,0x00,0x00,0x00,0x00,0x00,0x00,0x00,0x00,0x00,0x00,0x00,0x02,0x05,0x09,0x0C,0x0F,0x13,0x16,0x1A,0x1D,0x1E,0x1F,0x1F,0x1F,0x1F,0x1F,0x1F,0x1F,0x1F,0x1F,0x1F,0x1F,0x1F,0x1F,0x1F,0x1F,0x1F,0x1F,0x1F,0x1F,0x1F,0x1F,0x1F,0x1F,0x1F,0x1E,0x1C,0x19,0x16,0x12,0x0F,0x0B,0x08,0x04,0x02,0x01,0x00,0x00,0x00,
//Blue
0x1F,0x1F,0x1F,0x1F,0x1F,0x1F,0x1F,0x1F,0x1F,0x1F,0x1F,0x1F,0x1F,0x1F,0x1D,0x1B,0x18,0x16,0x13,0x10,0x0D,0x0A,0x06,0x03,0x02,0x00,0x00,0x00,0x01,0x00,0x00,0x00,0x00,0x00,0x00,0x00,0x00,0x01,0x00,0x00,0x00,0x00,0x00,0x00,0x00,0x00,0x00,0x00,0x00,0x00,0x00,0x01,0x00,0x00,0x00,0x00,0x00,0x00,0x00,0x00,0x00,0x00,0x00,0x00,
0x1F,0x1F,0x1F,0x1F,0x1F,0x1F,0x1F,0x1F,0x1F,0x1F,0x1F,0x1F,0x1F,0x1F,0x1E,0x1B,0x19,0x16,0x13,0x11,0x0E,0x0A,0x06,0x04,0x02,0x01,0x00,0x00,0x00,0x00,0x00,0x00,0x00,0x00,0x00,0x00,0x00,0x01,0x00,0x00,0x00,0x00,0x00,0x00,0x00,0x00,0x00,0x00,0x00,0x00,0x00,0x01,0x00,0x00,0x00,0x00,0x00,0x00,0x00,0x00,0x00,0x00,0x00,0x00,
0x1F,0x1F,0x1F,0x1F,0x1F,0x1E,0x1F,0x1F,0x1F,0x1F,0x1E,0x1E,0x1F,0x1F,0x1E,0x1C,0x1A,0x17,0x14,0x12,0x0F,0x0B,0x08,0x05,0x03,0x01,0x00,0x00,0x00,0x00,0x00,0x00,0x00,0x00,0x00,0x00,0x00,0x01,0x01,0x00,0x00,0x00,0x01,0x00,0x00,0x00,0x00,0x00,0x00,0x00,0x00,0x00,0x00,0x00,0x00,0x00,0x00,0x00,0x00,0x00,0x00,0x00,0x00,0x00,
0x1F,0x1F,0x1F,0x1F,0x1F,0x1E,0x1F,0x1F,0x1F,0x1F,0x1F,0x1F,0x1F,0x1F,0x1E,0x1D,0x1B,0x19,0x16,0x13,0x10,0x0D,0x09,0x06,0x04,0x02,0x01,0x00,0x00,0x00,0x00,0x00,0x00,0x00,0x00,0x00,0x00,0x01,0x00,0x00,0x00,0x00,0x01,0x01,0x00,0x00,0x00,0x00,0x00,0x00,0x00,0x00,0x00,0x00,0x00,0x00,0x00,0x00,0x00,0x00,0x00,0x00,0x00,0x00,
0x1F,0x1F,0x1F,0x1F,0x1F,0x1E,0x1F,0x1F,0x1F,0x1F,0x1F,0x1F,0x1F,0x1F,0x1F,0x1E,0x1C,0x1A,0x17,0x14,0x12,0x0F,0x0B,0x08,0x06,0x04,0x01,0x00,0x00,0x00,0x00,0x00,0x00,0x00,0x00,0x00,0x00,0x00,0x00,0x00,0x00,0x00,0x00,0x00,0x00,0x00,0x00,0x00,0x00,0x00,0x00,0x00,0x00,0x00,0x00,0x00,0x00,0x00,0x00,0x00,0x00,0x00,0x00,0x00,
0x1E,0x1F,0x1F,0x1F,0x1F,0x1F,0x1F,0x1F,0x1F,0x1F,0x1F,0x1F,0x1F,0x1F,0x1F,0x1F,0x1D,0x1B,0x18,0x16,0x13,0x10,0x0D,0x0A,0x07,0x05,0x02,0x00,0x00,0x00,0x00,0x00,0x00,0x00,0x01,0x00,0x00,0x00,0x00,0x00,0x00,0x00,0x00,0x00,0x00,0x00,0x00,0x00,0x00,0x00,0x00,0x00,0x00,0x00,0x00,0x00,0x00,0x00,0x00,0x00,0x00,0x00,0x00,0x00,
0x1F,0x1F,0x1F,0x1F,0x1F,0x1F,0x1F,0x1F,0x1F,0x1F,0x1F,0x1F,0x1F,0x1F,0x1F,0x1F,0x1E,0x1C,0x19,0x17,0x14,0x12,0x0E,0x0B,0x08,0x05,0x02,0x00,0x00,0x00,0x00,0x00,0x00,0x00,0x00,0x00,0x00,0x00,0x00,0x00,0x00,0x00,0x00,0x01,0x00,0x00,0x00,0x00,0x01,0x00,0x00,0x00,0x00,0x00,0x00,0x00,0x00,0x00,0x00,0x00,0x00,0x00,0x00,0x00,
0x1F,0x1F,0x1F,0x1F,0x1F,0x1F,0x1F,0x1F,0x1F,0x1F,0x1E,0x1F,0x1F,0x1F,0x1F,0x1F,0x1F,0x1D,0x1A,0x17,0x15,0x12,0x0E,0x0C,0x08,0x06,0x03,0x01,0x00,0x00,0x00,0x00,0x00,0x00,0x00,0x00,0x00,0x00,0x00,0x00,0x00,0x00,0x01,0x01,0x00,0x00,0x00,0x00,0x01,0x00,0x00,0x00,0x00,0x00,0x00,0x00,0x00,0x00,0x00,0x00,0x00,0x00,0x00,0x00,
0x1F,0x1F,0x1F,0x1F,0x1F,0x1F,0x1F,0x1F,0x1F,0x1F,0x1F,0x1F,0x1F,0x1F,0x1F,0x1F,0x1F,0x1E,0x1C,0x19,0x17,0x14,0x10,0x0D,0x0A,0x08,0x04,0x02,0x01,0x00,0x00,0x00,0x00,0x00,0x00,0x00,0x00,0x00,0x00,0x00,0x00,0x00,0x00,0x00,0x00,0x01,0x00,0x00,0x00,0x00,0x00,0x00,0x00,0x00,0x00,0x00,0x00,0x00,0x00,0x00,0x00,0x00,0x00,0x00,
0x1F,0x1F,0x1F,0x1F,0x1F,0x1E,0x1F,0x1F,0x1F,0x1F,0x1E,0x1F,0x1F,0x1F,0x1F,0x1F,0x1F,0x1E,0x1C,0x1A,0x18,0x15,0x11,0x0E,0x0B,0x08,0x05,0x03,0x01,0x00,0x00,0x00,0x00,0x00,0x00,0x00,0x00,0x00,0x00,0x00,0x00,0x00,0x00,0x00,0x01,0x01,0x00,0x00,0x01,0x00,0x00,0x00,0x00,0x00,0x00,0x00,0x00,0x00,0x00,0x00,0x00,0x00,0x00,0x00,
0x1F,0x1F,0x1F,0x1F,0x1F,0x1F,0x1F,0x1F,0x1F,0x1F,0x1E,0x1E,0x1F,0x1F,0x1F,0x1F,0x1F,0x1F,0x1D,0x1B,0x19,0x16,0x12,0x0F,0x0C,0x09,0x06,0x04,0x02,0x01,0x00,0x00,0x00,0x00,0x00,0x00,0x00,0x00,0x00,0x00,0x00,0x00,0x00,0x00,0x00,0x01,0x00,0x00,0x01,0x00,0x00,0x00,0x00,0x00,0x00,0x00,0x00,0x00,0x00,0x00,0x00,0x00,0x00,0x00,
0x1F,0x1F,0x1F,0x1F,0x1F,0x1F,0x1F,0x1F,0x1F,0x1F,0x1E,0x1E,0x1F,0x1F,0x1F,0x1F,0x1F,0x1F,0x1E,0x1C,0x1A,0x17,0x13,0x11,0x0E,0x0B,0x07,0x05,0x03,0x02,0x00,0x00,0x00,0x00,0x00,0x00,0x00,0x00,0x00,0x00,0x00,0x00,0x01,0x00,0x00,0x01,0x00,0x00,0x01,0x00,0x00,0x00,0x00,0x00,0x00,0x00,0x00,0x00,0x00,0x00,0x00,0x00,0x00,0x00,
0x1F,0x1F,0x1F,0x1F,0x1F,0x1F,0x1E,0x1F,0x1F,0x1F,0x1F,0x1E,0x1F,0x1F,0x1F,0x1F,0x1F,0x1F,0x1E,0x1D,0x1B,0x19,0x15,0x12,0x0F,0x0D,0x09,0x06,0x04,0x02,0x01,0x00,0x00,0x00,0x00,0x00,0x00,0x00,0x00,0x00,0x00,0x00,0x00,0x00,0x00,0x00,0x00,0x00,0x00,0x00,0x00,0x00,0x00,0x00,0x00,0x00,0x00,0x00,0x00,0x00,0x00,0x00,0x00,0x00,
0x1F,0x1F,0x1F,0x1F,0x1F,0x1F,0x1F,0x1F,0x1F,0x1F,0x1F,0x1F,0x1F,0x1F,0x1F,0x1F,0x1F,0x1F,0x1F,0x1E,0x1C,0x1A,0x17,0x14,0x11,0x0E,0x0A,0x07,0x05,0x03,0x01,0x00,0x00,0x00,0x00,0x00,0x00,0x00,0x00,0x00,0x00,0x00,0x00,0x00,0x00,0x00,0x00,0x00,0x00,0x00,0x00,0x00,0x00,0x00,0x00,0x00,0x00,0x00,0x00,0x00,0x00,0x00,0x00,0x00,
0x1F,0x1F,0x1F,0x1F,0x1F,0x1F,0x1F,0x1E,0x1F,0x1F,0x1F,0x1E,0x1F,0x1F,0x1F,0x1F,0x1F,0x1F,0x1F,0x1E,0x1E,0x1B,0x18,0x15,0x12,0x0F,0x0B,0x08,0x06,0x04,0x02,0x00,0x00,0x00,0x00,0x00,0x00,0x00,0x00,0x00,0x00,0x00,0x00,0x00,0x00,0x00,0x00,0x00,0x01,0x00,0x00,0x00,0x00,0x00,0x00,0x00,0x00,0x00,0x00,0x00,0x00,0x00,0x00,0x00,
0x1F,0x1F,0x1F,0x1F,0x1F,0x1F,0x1F,0x1F,0x1F,0x1F,0x1F,0x1E,0x1F,0x1F,0x1F,0x1F,0x1E,0x1F,0x1F,0x1F,0x1E,0x1B,0x18,0x16,0x13,0x10,0x0C,0x09,0x07,0x04,0x02,0x01,0x00,0x00,0x00,0x00,0x00,0x00,0x00,0x00,0x00,0x00,0x00,0x00,0x00,0x00,0x00,0x00,0x01,0x00,0x00,0x00,0x00,0x00,0x00,0x00,0x00,0x00,0x00,0x00,0x00,0x00,0x00,0x00,
0x1F,0x1F,0x1E,0x1F,0x1F,0x1F,0x1F,0x1F,0x1F,0x1F,0x1F,0x1F,0x1F,0x1F,0x1F,0x1F,0x1F,0x1F,0x1F,0x1F,0x1F,0x1D,0x1A,0x18,0x15,0x12,0x0F,0x0B,0x09,0x06,0x03,0x00,0x01,0x00,0x00,0x00,0x00,0x00,0x00,0x00,0x00,0x00,0x00,0x00,0x00,0x00,0x00,0x00,0x01,0x00,0x00,0x00,0x00,0x00,0x00,0x00,0x00,0x00,0x00,0x00,0x00,0x00,0x00,0x00,
0x1F,0x1F,0x1F,0x1F,0x1F,0x1F,0x1F,0x1F,0x1F,0x1F,0x1F,0x1F,0x1F,0x1E,0x1F,0x1F,0x1F,0x1F,0x1F,0x1F,0x1F,0x1E,0x1B,0x18,0x15,0x13,0x0F,0x0C,0x09,0x07,0x03,0x01,0x01,0x00,0x00,0x00,0x00,0x00,0x00,0x00,0x00,0x00,0x00,0x00,0x00,0x00,0x00,0x00,0x01,0x00,0x00,0x00,0x00,0x00,0x00,0x00,0x00,0x00,0x00,0x00,0x00,0x00,0x00,0x00,
0x1F,0x1F,0x1F,0x1F,0x1F,0x1F,0x1F,0x1F,0x1F,0x1F,0x1F,0x1F,0x1F,0x1E,0x1E,0x1F,0x1F,0x1F,0x1F,0x1F,0x1F,0x1E,0x1B,0x19,0x16,0x14,0x10,0x0D,0x0A,0x08,0x04,0x02,0x01,0x00,0x00,0x00,0x00,0x00,0x00,0x00,0x00,0x00,0x00,0x00,0x00,0x01,0x01,0x00,0x01,0x00,0x00,0x00,0x00,0x00,0x00,0x00,0x00,0x00,0x00,0x00,0x00,0x00,0x00,0x00,
0x1F,0x1F,0x1F,0x1F,0x1F,0x1F,0x1F,0x1F,0x1F,0x1F,0x1F,0x1F,0x1F,0x1F,0x1F,0x1F,0x1F,0x1F,0x1F,0x1F,0x1F,0x1F,0x1C,0x1A,0x18,0x15,0x12,0x0F,0x0C,0x09,0x05,0x03,0x02,0x00,0x00,0x00,0x00,0x00,0x00,0x00,0x00,0x00,0x00,0x00,0x00,0x01,0x00,0x00,0x01,0x00,0x00,0x00,0x00,0x00,0x00,0x00,0x00,0x00,0x00,0x00,0x00,0x00,0x00,0x00,
0x1F,0x1F,0x1F,0x1F,0x1F,0x1F,0x1F,0x1F,0x1F,0x1F,0x1F,0x1F,0x1F,0x1F,0x1F,0x1F,0x1F,0x1F,0x1F,0x1F,0x1F,0x1F,0x1D,0x1B,0x19,0x17,0x13,0x10,0x0E,0x0A,0x07,0x05,0x03,0x01,0x00,0x00,0x00,0x00,0x00,0x00,0x00,0x00,0x00,0x00,0x00,0x01,0x00,0x00,0x00,0x00,0x00,0x00,0x00,0x00,0x00,0x00,0x00,0x00,0x00,0x00,0x00,0x00,0x00,0x00,
0x1F,0x1F,0x1F,0x1F,0x1F,0x1F,0x1F,0x1F,0x1F,0x1F,0x1F,0x1F,0x1F,0x1F,0x1F,0x1F,0x1F,0x1F,0x1F,0x1F,0x1F,0x1F,0x1E,0x1D,0x1B,0x18,0x15,0x12,0x0F,0x0C,0x09,0x06,0x03,0x02,0x00,0x00,0x00,0x00,0x00,0x00,0x00,0x00,0x00,0x00,0x00,0x00,0x00,0x00,0x00,0x00,0x00,0x00,0x00,0x00,0x00,0x00,0x00,0x00,0x00,0x00,0x00,0x00,0x00,0x00,
0x1F,0x1F,0x1F,0x1F,0x1F,0x1F,0x1F,0x1F,0x1F,0x1F,0x1F,0x1F,0x1F,0x1F,0x1F,0x1F,0x1F,0x1F,0x1E,0x1F,0x1F,0x1F,0x1F,0x1E,0x1B,0x19,0x16,0x13,0x10,0x0D,0x09,0x07,0x04,0x02,0x00,0x00,0x00,0x00,0x00,0x00,0x00,0x00,0x00,0x00,0x00,0x00,0x00,0x00,0x00,0x00,0x00,0x00,0x01,0x01,0x00,0x00,0x00,0x00,0x00,0x00,0x00,0x00,0x00,0x00,
0x1F,0x1F,0x1F,0x1F,0x1F,0x1F,0x1F,0x1F,0x1F,0x1F,0x1F,0x1F,0x1F,0x1F,0x1F,0x1F,0x1F,0x1E,0x1E,0x1E,0x1F,0x1F,0x1F,0x1E,0x1C,0x1A,0x16,0x13,0x11,0x0E,0x0A,0x08,0x04,0x02,0x00,0x00,0x00,0x00,0x00,0x00,0x00,0x00,0x00,0x00,0x00,0x00,0x00,0x00,0x00,0x00,0x00,0x00,0x01,0x01,0x00,0x00,0x01,0x00,0x00,0x00,0x00,0x00,0x00,0x00,
0x1F,0x1F,0x1F,0x1F,0x1E,0x1E,0x1F,0x1F,0x1E,0x1F,0x1F,0x1F,0x1F,0x1F,0x1F,0x1F,0x1F,0x1F,0x1F,0x1F,0x1F,0x1F,0x1F,0x1E,0x1D,0x1B,0x19,0x16,0x14,0x10,0x0B,0x08,0x06,0x04,0x01,0x00,0x00,0x00,0x00,0x00,0x00,0x00,0x01,0x01,0x00,0x00,0x00,0x00,0x00,0x00,0x00,0x00,0x00,0x00,0x00,0x00,0x01,0x00,0x00,0x00,0x00,0x00,0x00,0x00,
0x1F,0x1F,0x1F,0x1F,0x1E,0x1E,0x1F,0x1F,0x1F,0x1F,0x1F,0x1F,0x1F,0x1F,0x1F,0x1F,0x1F,0x1F,0x1F,0x1F,0x1F,0x1F,0x1E,0x1E,0x1E,0x1C,0x19,0x17,0x14,0x10,0x0C,0x09,0x07,0x04,0x02,0x00,0x00,0x00,0x00,0x00,0x00,0x00,0x01,0x00,0x00,0x00,0x00,0x00,0x00,0x00,0x00,0x00,0x01,0x01,0x00,0x00,0x01,0x00,0x00,0x00,0x00,0x00,0x00,0x00,
0x1F,0x1F,0x1F,0x1F,0x1E,0x1F,0x1F,0x1F,0x1F,0x1F,0x1F,0x1F,0x1F,0x1E,0x1E,0x1F,0x1F,0x1F,0x1E,0x1F,0x1F,0x1F,0x1F,0x1E,0x1E,0x1C,0x1A,0x17,0x15,0x12,0x0D,0x0A,0x08,0x06,0x03,0x01,0x00,0x00,0x00,0x00,0x00,0x00,0x00,0x00,0x00,0x00,0x00,0x00,0x01,0x00,0x00,0x00,0x01,0x01,0x00,0x00,0x01,0x00,0x00,0x00,0x00,0x00,0x00,0x00,
0x1D,0x1F,0x1F,0x1F,0x1F,0x1F,0x1F,0x1F,0x1F,0x1F,0x1F,0x1F,0x1F,0x1E,0x1E,0x1F,0x1F,0x1F,0x1E,0x1F,0x1F,0x1F,0x1F,0x1F,0x1F,0x1D,0x1B,0x19,0x16,0x13,0x0F,0x0C,0x09,0x07,0x04,0x02,0x01,0x00,0x00,0x00,0x00,0x00,0x00,0x00,0x00,0x00,0x00,0x00,0x01,0x00,0x00,0x00,0x00,0x00,0x00,0x00,0x01,0x00,0x00,0x00,0x00,0x00,0x00,0x00,
0x1C,0x1E,0x1F,0x1F,0x1F,0x1F,0x1F,0x1F,0x1F,0x1F,0x1F,0x1F,0x1F,0x1E,0x1E,0x1F,0x1F,0x1F,0x1F,0x1F,0x1F,0x1F,0x1F,0x1F,0x1F,0x1E,0x1C,0x1A,0x17,0x15,0x11,0x0E,0x0B,0x08,0x05,0x03,0x02,0x01,0x00,0x00,0x00,0x00,0x00,0x00,0x00,0x00,0x00,0x00,0x00,0x00,0x00,0x00,0x00,0x00,0x00,0x00,0x00,0x00,0x00,0x00,0x00,0x00,0x00,0x00,
0x1B,0x1D,0x1F,0x1F,0x1F,0x1F,0x1F,0x1F,0x1F,0x1F,0x1F,0x1F,0x1F,0x1F,0x1F,0x1F,0x1F,0x1F,0x1F,0x1F,0x1F,0x1F,0x1F,0x1F,0x1F,0x1F,0x1D,0x1B,0x19,0x16,0x13,0x10,0x0C,0x09,0x06,0x04,0x03,0x01,0x00,0x00,0x00,0x00,0x00,0x00,0x00,0x00,0x00,0x00,0x00,0x00,0x00,0x00,0x00,0x00,0x00,0x00,0x00,0x00,0x00,0x00,0x01,0x00,0x00,0x00,
0x1A,0x1C,0x1E,0x1F,0x1F,0x1F,0x1F,0x1F,0x1F,0x1F,0x1F,0x1F,0x1F,0x1F,0x1F,0x1F,0x1F,0x1F,0x1F,0x1E,0x1F,0x1F,0x1F,0x1F,0x1F,0x1F,0x1E,0x1B,0x1A,0x17,0x14,0x11,0x0D,0x0A,0x07,0x05,0x03,0x02,0x00,0x00,0x00,0x00,0x00,0x00,0x00,0x00,0x00,0x00,0x00,0x00,0x00,0x00,0x00,0x00,0x01,0x00,0x00,0x00,0x00,0x00,0x01,0x01,0x00,0x00,
0x19,0x1C,0x1E,0x1F,0x1F,0x1F,0x1F,0x1F,0x1F,0x1F,0x1F,0x1F,0x1F,0x1F,0x1F,0x1F,0x1F,0x1F,0x1E,0x1E,0x1F,0x1F,0x1F,0x1F,0x1F,0x1F,0x1E,0x1C,0x1B,0x18,0x15,0x11,0x0E,0x0B,0x08,0x05,0x04,0x02,0x00,0x00,0x00,0x00,0x00,0x00,0x00,0x00,0x00,0x00,0x00,0x00,0x00,0x00,0x00,0x01,0x01,0x00,0x00,0x00,0x00,0x01,0x01,0x01,0x00,0x00,

};
void nghich_dao() // du lieu adc doc duoc can phai dua qua ham nay de xu li (goi ham nay 1 lan duy nhat truoc khi tinh FFT)
{
   unsigned int i;
   i=RE[  1]; RE[  1]=RE[256]; RE[256]=i;
   i=RE[  2]; RE[  2]=RE[128]; RE[128]=i;
   i=RE[  3]; RE[  3]=RE[384]; RE[384]=i;
   i=RE[  4]; RE[  4]=RE[ 64]; RE[ 64]=i;
   i=RE[  5]; RE[  5]=RE[320]; RE[320]=i;
   i=RE[  6]; RE[  6]=RE[192]; RE[192]=i;
   i=RE[  7]; RE[  7]=RE[448]; RE[448]=i;
   i=RE[  8]; RE[  8]=RE[ 32]; RE[ 32]=i;
   i=RE[  9]; RE[  9]=RE[288]; RE[288]=i;
   i=RE[ 10]; RE[ 10]=RE[160]; RE[160]=i;
   i=RE[ 11]; RE[ 11]=RE[416]; RE[416]=i;
   i=RE[ 12]; RE[ 12]=RE[ 96]; RE[ 96]=i;
   i=RE[ 13]; RE[ 13]=RE[352]; RE[352]=i;
   i=RE[ 14]; RE[ 14]=RE[224]; RE[224]=i;
   i=RE[ 15]; RE[ 15]=RE[480]; RE[480]=i;
   i=RE[ 17]; RE[ 17]=RE[272]; RE[272]=i;
   i=RE[ 18]; RE[ 18]=RE[144]; RE[144]=i;
   i=RE[ 19]; RE[ 19]=RE[400]; RE[400]=i;
   i=RE[ 20]; RE[ 20]=RE[ 80]; RE[ 80]=i;
   i=RE[ 21]; RE[ 21]=RE[336]; RE[336]=i;
   i=RE[ 22]; RE[ 22]=RE[208]; RE[208]=i;
   i=RE[ 23]; RE[ 23]=RE[464]; RE[464]=i;
   i=RE[ 24]; RE[ 24]=RE[ 48]; RE[ 48]=i;
   i=RE[ 25]; RE[ 25]=RE[304]; RE[304]=i;
   i=RE[ 26]; RE[ 26]=RE[176]; RE[176]=i;
   i=RE[ 27]; RE[ 27]=RE[432]; RE[432]=i;
   i=RE[ 28]; RE[ 28]=RE[112]; RE[112]=i;
   i=RE[ 29]; RE[ 29]=RE[368]; RE[368]=i;
   i=RE[ 30]; RE[ 30]=RE[240]; RE[240]=i;
   i=RE[ 31]; RE[ 31]=RE[496]; RE[496]=i;
   i=RE[ 33]; RE[ 33]=RE[264]; RE[264]=i;
   i=RE[ 34]; RE[ 34]=RE[136]; RE[136]=i;
   i=RE[ 35]; RE[ 35]=RE[392]; RE[392]=i;
   i=RE[ 36]; RE[ 36]=RE[ 72]; RE[ 72]=i;
   i=RE[ 37]; RE[ 37]=RE[328]; RE[328]=i;
   i=RE[ 38]; RE[ 38]=RE[200]; RE[200]=i;
   i=RE[ 39]; RE[ 39]=RE[456]; RE[456]=i;
   i=RE[ 41]; RE[ 41]=RE[296]; RE[296]=i;
   i=RE[ 42]; RE[ 42]=RE[168]; RE[168]=i;
   i=RE[ 43]; RE[ 43]=RE[424]; RE[424]=i;
   i=RE[ 44]; RE[ 44]=RE[104]; RE[104]=i;
   i=RE[ 45]; RE[ 45]=RE[360]; RE[360]=i;
   i=RE[ 46]; RE[ 46]=RE[232]; RE[232]=i;
   i=RE[ 47]; RE[ 47]=RE[488]; RE[488]=i;
   i=RE[ 49]; RE[ 49]=RE[280]; RE[280]=i;
   i=RE[ 50]; RE[ 50]=RE[152]; RE[152]=i;
   i=RE[ 51]; RE[ 51]=RE[408]; RE[408]=i;
   i=RE[ 52]; RE[ 52]=RE[ 88]; RE[ 88]=i;
   i=RE[ 53]; RE[ 53]=RE[344]; RE[344]=i;
   i=RE[ 54]; RE[ 54]=RE[216]; RE[216]=i;
   i=RE[ 55]; RE[ 55]=RE[472]; RE[472]=i;
   i=RE[ 57]; RE[ 57]=RE[312]; RE[312]=i;
   i=RE[ 58]; RE[ 58]=RE[184]; RE[184]=i;
   i=RE[ 59]; RE[ 59]=RE[440]; RE[440]=i;
   i=RE[ 60]; RE[ 60]=RE[120]; RE[120]=i;
   i=RE[ 61]; RE[ 61]=RE[376]; RE[376]=i;
   i=RE[ 62]; RE[ 62]=RE[248]; RE[248]=i;
   i=RE[ 63]; RE[ 63]=RE[504]; RE[504]=i;
   i=RE[ 65]; RE[ 65]=RE[260]; RE[260]=i;
   i=RE[ 66]; RE[ 66]=RE[132]; RE[132]=i;
   i=RE[ 67]; RE[ 67]=RE[388]; RE[388]=i;
   i=RE[ 69]; RE[ 69]=RE[324]; RE[324]=i;
   i=RE[ 70]; RE[ 70]=RE[196]; RE[196]=i;
   i=RE[ 71]; RE[ 71]=RE[452]; RE[452]=i;
   i=RE[ 73]; RE[ 73]=RE[292]; RE[292]=i;
   i=RE[ 74]; RE[ 74]=RE[164]; RE[164]=i;
   i=RE[ 75]; RE[ 75]=RE[420]; RE[420]=i;
   i=RE[ 76]; RE[ 76]=RE[100]; RE[100]=i;
   i=RE[ 77]; RE[ 77]=RE[356]; RE[356]=i;
   i=RE[ 78]; RE[ 78]=RE[228]; RE[228]=i;
   i=RE[ 79]; RE[ 79]=RE[484]; RE[484]=i;
   i=RE[ 81]; RE[ 81]=RE[276]; RE[276]=i;
   i=RE[ 82]; RE[ 82]=RE[148]; RE[148]=i;
   i=RE[ 83]; RE[ 83]=RE[404]; RE[404]=i;
   i=RE[ 85]; RE[ 85]=RE[340]; RE[340]=i;
   i=RE[ 86]; RE[ 86]=RE[212]; RE[212]=i;
   i=RE[ 87]; RE[ 87]=RE[468]; RE[468]=i;
   i=RE[ 89]; RE[ 89]=RE[308]; RE[308]=i;
   i=RE[ 90]; RE[ 90]=RE[180]; RE[180]=i;
   i=RE[ 91]; RE[ 91]=RE[436]; RE[436]=i;
   i=RE[ 92]; RE[ 92]=RE[116]; RE[116]=i;
   i=RE[ 93]; RE[ 93]=RE[372]; RE[372]=i;
   i=RE[ 94]; RE[ 94]=RE[244]; RE[244]=i;
   i=RE[ 95]; RE[ 95]=RE[500]; RE[500]=i;
   i=RE[ 97]; RE[ 97]=RE[268]; RE[268]=i;
   i=RE[ 98]; RE[ 98]=RE[140]; RE[140]=i;
   i=RE[ 99]; RE[ 99]=RE[396]; RE[396]=i;
   i=RE[101]; RE[101]=RE[332]; RE[332]=i;
   i=RE[102]; RE[102]=RE[204]; RE[204]=i;
   i=RE[103]; RE[103]=RE[460]; RE[460]=i;
   i=RE[105]; RE[105]=RE[300]; RE[300]=i;
   i=RE[106]; RE[106]=RE[172]; RE[172]=i;
   i=RE[107]; RE[107]=RE[428]; RE[428]=i;
   i=RE[109]; RE[109]=RE[364]; RE[364]=i;
   i=RE[110]; RE[110]=RE[236]; RE[236]=i;
   i=RE[111]; RE[111]=RE[492]; RE[492]=i;
   i=RE[113]; RE[113]=RE[284]; RE[284]=i;
   i=RE[114]; RE[114]=RE[156]; RE[156]=i;
   i=RE[115]; RE[115]=RE[412]; RE[412]=i;
   i=RE[117]; RE[117]=RE[348]; RE[348]=i;
   i=RE[118]; RE[118]=RE[220]; RE[220]=i;
   i=RE[119]; RE[119]=RE[476]; RE[476]=i;
   i=RE[121]; RE[121]=RE[316]; RE[316]=i;
   i=RE[122]; RE[122]=RE[188]; RE[188]=i;
   i=RE[123]; RE[123]=RE[444]; RE[444]=i;
   i=RE[125]; RE[125]=RE[380]; RE[380]=i;
   i=RE[126]; RE[126]=RE[252]; RE[252]=i;
   i=RE[127]; RE[127]=RE[508]; RE[508]=i;
   i=RE[129]; RE[129]=RE[258]; RE[258]=i;
   i=RE[131]; RE[131]=RE[386]; RE[386]=i;
   i=RE[133]; RE[133]=RE[322]; RE[322]=i;
   i=RE[134]; RE[134]=RE[194]; RE[194]=i;
   i=RE[135]; RE[135]=RE[450]; RE[450]=i;
   i=RE[137]; RE[137]=RE[290]; RE[290]=i;
   i=RE[138]; RE[138]=RE[162]; RE[162]=i;
   i=RE[139]; RE[139]=RE[418]; RE[418]=i;
   i=RE[141]; RE[141]=RE[354]; RE[354]=i;
   i=RE[142]; RE[142]=RE[226]; RE[226]=i;
   i=RE[143]; RE[143]=RE[482]; RE[482]=i;
   i=RE[145]; RE[145]=RE[274]; RE[274]=i;
   i=RE[147]; RE[147]=RE[402]; RE[402]=i;
   i=RE[149]; RE[149]=RE[338]; RE[338]=i;
   i=RE[150]; RE[150]=RE[210]; RE[210]=i;
   i=RE[151]; RE[151]=RE[466]; RE[466]=i;
   i=RE[153]; RE[153]=RE[306]; RE[306]=i;
   i=RE[154]; RE[154]=RE[178]; RE[178]=i;
   i=RE[155]; RE[155]=RE[434]; RE[434]=i;
   i=RE[157]; RE[157]=RE[370]; RE[370]=i;
   i=RE[158]; RE[158]=RE[242]; RE[242]=i;
   i=RE[159]; RE[159]=RE[498]; RE[498]=i;
   i=RE[161]; RE[161]=RE[266]; RE[266]=i;
   i=RE[163]; RE[163]=RE[394]; RE[394]=i;
   i=RE[165]; RE[165]=RE[330]; RE[330]=i;
   i=RE[166]; RE[166]=RE[202]; RE[202]=i;
   i=RE[167]; RE[167]=RE[458]; RE[458]=i;
   i=RE[169]; RE[169]=RE[298]; RE[298]=i;
   i=RE[171]; RE[171]=RE[426]; RE[426]=i;
   i=RE[173]; RE[173]=RE[362]; RE[362]=i;
   i=RE[174]; RE[174]=RE[234]; RE[234]=i;
   i=RE[175]; RE[175]=RE[490]; RE[490]=i;
   i=RE[177]; RE[177]=RE[282]; RE[282]=i;
   i=RE[179]; RE[179]=RE[410]; RE[410]=i;
   i=RE[181]; RE[181]=RE[346]; RE[346]=i;
   i=RE[182]; RE[182]=RE[218]; RE[218]=i;
   i=RE[183]; RE[183]=RE[474]; RE[474]=i;
   i=RE[185]; RE[185]=RE[314]; RE[314]=i;
   i=RE[187]; RE[187]=RE[442]; RE[442]=i;
   i=RE[189]; RE[189]=RE[378]; RE[378]=i;
   i=RE[190]; RE[190]=RE[250]; RE[250]=i;
   i=RE[191]; RE[191]=RE[506]; RE[506]=i;
   i=RE[193]; RE[193]=RE[262]; RE[262]=i;
   i=RE[195]; RE[195]=RE[390]; RE[390]=i;
   i=RE[197]; RE[197]=RE[326]; RE[326]=i;
   i=RE[199]; RE[199]=RE[454]; RE[454]=i;
   i=RE[201]; RE[201]=RE[294]; RE[294]=i;
   i=RE[203]; RE[203]=RE[422]; RE[422]=i;
   i=RE[205]; RE[205]=RE[358]; RE[358]=i;
   i=RE[206]; RE[206]=RE[230]; RE[230]=i;
   i=RE[207]; RE[207]=RE[486]; RE[486]=i;
   i=RE[209]; RE[209]=RE[278]; RE[278]=i;
   i=RE[211]; RE[211]=RE[406]; RE[406]=i;
   i=RE[213]; RE[213]=RE[342]; RE[342]=i;
   i=RE[215]; RE[215]=RE[470]; RE[470]=i;
   i=RE[217]; RE[217]=RE[310]; RE[310]=i;
   i=RE[219]; RE[219]=RE[438]; RE[438]=i;
   i=RE[221]; RE[221]=RE[374]; RE[374]=i;
   i=RE[222]; RE[222]=RE[246]; RE[246]=i;
   i=RE[223]; RE[223]=RE[502]; RE[502]=i;
   i=RE[225]; RE[225]=RE[270]; RE[270]=i;
   i=RE[227]; RE[227]=RE[398]; RE[398]=i;
   i=RE[229]; RE[229]=RE[334]; RE[334]=i;
   i=RE[231]; RE[231]=RE[462]; RE[462]=i;
   i=RE[233]; RE[233]=RE[302]; RE[302]=i;
   i=RE[235]; RE[235]=RE[430]; RE[430]=i;
   i=RE[237]; RE[237]=RE[366]; RE[366]=i;
   i=RE[239]; RE[239]=RE[494]; RE[494]=i;
   i=RE[241]; RE[241]=RE[286]; RE[286]=i;
   i=RE[243]; RE[243]=RE[414]; RE[414]=i;
   i=RE[245]; RE[245]=RE[350]; RE[350]=i;
   i=RE[247]; RE[247]=RE[478]; RE[478]=i;
   i=RE[249]; RE[249]=RE[318]; RE[318]=i;
   i=RE[251]; RE[251]=RE[446]; RE[446]=i;
   i=RE[253]; RE[253]=RE[382]; RE[382]=i;
   i=RE[255]; RE[255]=RE[510]; RE[510]=i;
   i=RE[259]; RE[259]=RE[385]; RE[385]=i;
   i=RE[261]; RE[261]=RE[321]; RE[321]=i;
   i=RE[263]; RE[263]=RE[449]; RE[449]=i;
   i=RE[265]; RE[265]=RE[289]; RE[289]=i;
   i=RE[267]; RE[267]=RE[417]; RE[417]=i;
   i=RE[269]; RE[269]=RE[353]; RE[353]=i;
   i=RE[271]; RE[271]=RE[481]; RE[481]=i;
   i=RE[275]; RE[275]=RE[401]; RE[401]=i;
   i=RE[277]; RE[277]=RE[337]; RE[337]=i;
   i=RE[279]; RE[279]=RE[465]; RE[465]=i;
   i=RE[281]; RE[281]=RE[305]; RE[305]=i;
   i=RE[283]; RE[283]=RE[433]; RE[433]=i;
   i=RE[285]; RE[285]=RE[369]; RE[369]=i;
   i=RE[287]; RE[287]=RE[497]; RE[497]=i;
   i=RE[291]; RE[291]=RE[393]; RE[393]=i;
   i=RE[293]; RE[293]=RE[329]; RE[329]=i;
   i=RE[295]; RE[295]=RE[457]; RE[457]=i;
   i=RE[299]; RE[299]=RE[425]; RE[425]=i;
   i=RE[301]; RE[301]=RE[361]; RE[361]=i;
   i=RE[303]; RE[303]=RE[489]; RE[489]=i;
   i=RE[307]; RE[307]=RE[409]; RE[409]=i;
   i=RE[309]; RE[309]=RE[345]; RE[345]=i;
   i=RE[311]; RE[311]=RE[473]; RE[473]=i;
   i=RE[315]; RE[315]=RE[441]; RE[441]=i;
   i=RE[317]; RE[317]=RE[377]; RE[377]=i;
   i=RE[319]; RE[319]=RE[505]; RE[505]=i;
   i=RE[323]; RE[323]=RE[389]; RE[389]=i;
   i=RE[327]; RE[327]=RE[453]; RE[453]=i;
   i=RE[331]; RE[331]=RE[421]; RE[421]=i;
   i=RE[333]; RE[333]=RE[357]; RE[357]=i;
   i=RE[335]; RE[335]=RE[485]; RE[485]=i;
   i=RE[339]; RE[339]=RE[405]; RE[405]=i;
   i=RE[343]; RE[343]=RE[469]; RE[469]=i;
   i=RE[347]; RE[347]=RE[437]; RE[437]=i;
   i=RE[349]; RE[349]=RE[373]; RE[373]=i;
   i=RE[351]; RE[351]=RE[501]; RE[501]=i;
   i=RE[355]; RE[355]=RE[397]; RE[397]=i;
   i=RE[359]; RE[359]=RE[461]; RE[461]=i;
   i=RE[363]; RE[363]=RE[429]; RE[429]=i;
   i=RE[367]; RE[367]=RE[493]; RE[493]=i;
   i=RE[371]; RE[371]=RE[413]; RE[413]=i;
   i=RE[375]; RE[375]=RE[477]; RE[477]=i;
   i=RE[379]; RE[379]=RE[445]; RE[445]=i;
   i=RE[383]; RE[383]=RE[509]; RE[509]=i;
   i=RE[391]; RE[391]=RE[451]; RE[451]=i;
   i=RE[395]; RE[395]=RE[419]; RE[419]=i;
   i=RE[399]; RE[399]=RE[483]; RE[483]=i;
   i=RE[407]; RE[407]=RE[467]; RE[467]=i;
   i=RE[411]; RE[411]=RE[435]; RE[435]=i;
   i=RE[415]; RE[415]=RE[499]; RE[499]=i;
   i=RE[423]; RE[423]=RE[459]; RE[459]=i;
   i=RE[431]; RE[431]=RE[491]; RE[491]=i;
   i=RE[439]; RE[439]=RE[475]; RE[475]=i;
   i=RE[447]; RE[447]=RE[507]; RE[507]=i;
   i=RE[463]; RE[463]=RE[487]; RE[487]=i;
   i=RE[479]; RE[479]=RE[503]; RE[503]=i;
}

void FFT() //ham tinh FFT
{
    int thuc_W, ao_W ;
    int temp_N=2,index=1,dem=0;
	  int thuc_Ek,ao_Ek,KQ_thuc,KQ_ao;
	  nghich_dao();
    for(int buoc=0;buoc<log2N;buoc++)
    {
		 for(int k=0;k<index;k++)
        {
		     thuc_W = Cos_table[dem];
		     ao_W =   Sin_table[dem];
	       for(int i=k;i<N;i+=temp_N)
					{
						thuc_Ek = RE[i];
						ao_Ek = IM[i];

					  KQ_thuc = (thuc_W * RE[i+index] - ao_W * IM[i+index])/100;
						KQ_ao = (thuc_W * IM[i+index]  + RE[i+index] * ao_W)/100;

						RE[i]   =  thuc_Ek + KQ_thuc;
						RE[i+index] =  thuc_Ek - KQ_thuc;

						IM[i]   = ao_Ek + KQ_ao;
						IM[i+index] = ao_Ek - KQ_ao;
					}
			    dem++;
		     }
		  index   <<=1;
		  temp_N  <<=1;
    }
}

unsigned char led[16][8][64]={0};
void P5_display()
{
 for(int hang=0;hang<16;hang++)
 {
	for(int ts=0;ts<5;ts++)
	{
	 for(int i=0;i<64;i++)
	 {
		 led[hang][ts][i]=0;
		 if((display[1][16+hang][i] & (1<<ts)) != 0 ){led[hang][ts][i]|=0x04;} //ghi bit 2 G2
		 if((display[1][0+hang][i] & (1<<ts)) != 0 ){led[hang][ts][i]|=0x08;} //ghi bit 3 G1
		 if((display[0][0+hang][i] & (1<<ts)) != 0 ){led[hang][ts][i]|=0x10;} //ghi bit 4 R1
		 if((display[2][0+hang][i] & (1<<ts)) != 0 ){led[hang][ts][i]|=0x20;} //ghi bit 5 B1
		 if((display[0][16+hang][i] & (1<<ts)) != 0 ){led[hang][ts][i]|=0x40;} //ghi bit 6 R2
		 if((display[2][16+hang][i] & (1<<ts)) != 0 ){led[hang][ts][i]|=0x80;} //ghi bit 7 B2
	 }
	}
 }
}
void hang(char so)
{
	switch(so)
	{
    case 0:D_P->BSRR=(1<<(D+16));C_P->BSRR=(1<<(C+16));B_P->BSRR=(1<<(B+16));A_P->BSRR=(1<<(A+16));break;
    case 1:D_P->BSRR=(1<<(D+16));C_P->BSRR=(1<<(C+16));B_P->BSRR=(1<<(B+16));A_P->BSRR=(1<<A);break;
		case 2:D_P->BSRR=(1<<(D+16));C_P->BSRR=(1<<(C+16));B_P->BSRR=(1<<B);A_P->BSRR=(1<<(A+16));break;
		case 3:D_P->BSRR=(1<<(D+16));C_P->BSRR=(1<<(C+16));B_P->BSRR=(1<<B);A_P->BSRR=(1<<A);break;
    case 4:D_P->BSRR=(1<<(D+16));C_P->BSRR=(1<<C);B_P->BSRR=(1<<(B+16));A_P->BSRR=(1<<(A+16));break;
		case 5:D_P->BSRR=(1<<(D+16));C_P->BSRR=(1<<C);B_P->BSRR=(1<<(B+16));A_P->BSRR=(1<<A);break;
		case 6:D_P->BSRR=(1<<(D+16));C_P->BSRR=(1<<C);B_P->BSRR=(1<<B);A_P->BSRR=(1<<(A+16));break;
		case 7:D_P->BSRR=(1<<(D+16));C_P->BSRR=(1<<C);B_P->BSRR=(1<<B);A_P->BSRR=(1<<A);break;
		case 8:D_P->BSRR=(1<<D);C_P->BSRR=(1<<(C+16));B_P->BSRR=(1<<(B+16));A_P->BSRR=(1<<(A+16));break;
		case 9:D_P->BSRR=(1<<D);C_P->BSRR=(1<<(C+16));B_P->BSRR=(1<<(B+16));A_P->BSRR=(1<<A);break;
		case 10:D_P->BSRR=(1<<D);C_P->BSRR=(1<<(C+16));B_P->BSRR=(1<<B);A_P->BSRR=(1<<(A+16));break;
		case 11:D_P->BSRR=(1<<D);C_P->BSRR=(1<<(C+16));B_P->BSRR=(1<<B);A_P->BSRR=(1<<A);break;
		case 12:D_P->BSRR=(1<<D);C_P->BSRR=(1<<C);B_P->BSRR=(1<<(B+16));A_P->BSRR=(1<<(A+16));break;
		case 13:D_P->BSRR=(1<<D);C_P->BSRR=(1<<C);B_P->BSRR=(1<<(B+16));A_P->BSRR=(1<<A);break;
		case 14:D_P->BSRR=(1<<D);C_P->BSRR=(1<<C);B_P->BSRR=(1<<B);A_P->BSRR=(1<<(A+16));break;
		case 15:D_P->BSRR=(1<<D);C_P->BSRR=(1<<C);B_P->BSRR=(1<<B);A_P->BSRR=(1<<A);break;
	}
}

//void LCD_xoamanhinh()
//{
//	for(int mau=0;mau<3;mau++)
//	 for(int x=0;x<64;x++)
//	  for(int y=0;y<32;y++)
//	     display[mau][y][x]=0;
//}

void HAL_TIM_PeriodElapsedCallback(TIM_HandleTypeDef *htim) //ngat time
{
    if(htim->Instance==TIM2)
			 {
				 for(int i=0;i<128;i++)data_M[i]--;
			 }
		if(htim->Instance==TIM4)
			 {

            TIM4 -> PSC = timer_clock[vitri_bit]; 	 // nap gia tri chia moi
						TIM4->EGR = 1;                           //set EGR len 1 de load lai PSC
				    TIM4 ->SR = 0xFFFFFFFE;                  //xoa co ngat

            for(int i=0;i<64;i++){GPIOA->ODR=led[hang_led][vitri_bit][i];clk_P->BSRR=(1<<clk);}
						//tat hien thi
						GPIOB -> BSRR =(1<<OE);
						hang(hang_led);

						xuat_P->BSRR=(1<<xuat); // chot data
						xuat_P->BSRR=(1<<(xuat+16));

						GPIOB -> BSRR =(1<<(OE+16));

            vitri_bit++;
						if(vitri_bit==5){vitri_bit=0;hang_led++;if(hang_led==16)hang_led=0;}
			 }
}

void save_data()
{
  for(int i=0;i<40;i++) //40 cot dau
	 {
		 if(RE[i] > data_M[i])data_M[i] = RE[i];
		 else data_M[i]-=2000;
	 }
  for(int i=0;i<24;i++) //24 cot sau
	 {
		 char y=i+40;
		 int32_t temp = (RE[i*3+40] + RE[i*3+41]	+ RE[i*3+42])/2;
		 if(temp > data_M[y])data_M[y] = temp;
		 else data_M[y]-=2000;
	 }
}
void resize_data()
{
	for(int i=0;i<64;i++)
	{
					 if(data_M[i] < 2000)data_MT[i]=0;
			else if(data_M[i] < 2500)data_MT[i]=1;
			else if(data_M[i] < 3000)data_MT[i]=2;
			else if(data_M[i] < 3500)data_MT[i]=3;
			else if(data_M[i] < 4000)data_MT[i]=4;
			else if(data_M[i] < 4500)data_MT[i]=5;
			else if(data_M[i] < 5000)data_MT[i]=6;
			else if(data_M[i] < 6000)data_MT[i]=7;
			else if(data_M[i] < 7000)data_MT[i]=8;
			else if(data_M[i] < 8000)data_MT[i]=9;
			else if(data_M[i] < 9000)data_MT[i]=10;
			else if(data_M[i] < 10000)data_MT[i]=11;
			else if(data_M[i] < 11000)data_MT[i]=12;
			else if(data_M[i] < 12000)data_MT[i]=13;
			else if(data_M[i] < 13000)data_MT[i]=14;
			else if(data_M[i] < 14000)data_MT[i]=15;
			else if(data_M[i] < 15500)data_MT[i]=16;
			else if(data_M[i] < 17000)data_MT[i]=17;
			else if(data_M[i] < 18500)data_MT[i]=18;
			else if(data_M[i] < 20000)data_MT[i]=19;
			else if(data_M[i] < 21500)data_MT[i]=20;
			else if(data_M[i] < 23000)data_MT[i]=21;
			else if(data_M[i] < 24500)data_MT[i]=22;
			else if(data_M[i] < 26000)data_MT[i]=23;
			else if(data_M[i] < 28000)data_MT[i]=24;
			else if(data_M[i] < 30000)data_MT[i]=25;
			else if(data_M[i] < 32000)data_MT[i]=26;
			else if(data_M[i] < 34000)data_MT[i]=27;
			else if(data_M[i] < 36000)data_MT[i]=28;
			else if(data_M[i] < 38000)data_MT[i]=29;
			else if(data_M[i] < 40000)data_MT[i]=30;
			else data_MT[i]=31;
    }
}
/* USER CODE END PFP */

int main(void)
{

  /* MCU Configuration----------------------------------------------------------*/

  /* Reset of all peripherals, Initializes the Flash interface and the Systick. */
  HAL_Init();

  /* Configure the system clock */
  SystemClock_Config();

  /* Initialize all configured peripherals */
  MX_GPIO_Init();
  MX_TIM2_Init();
  MX_ADC1_Init();
  MX_TIM4_Init();
  MX_TIM3_Init();
  /* USER CODE BEGIN 2 */
	    //HAL_TIM_PWM_Start(&htim2,TIM_CHANNEL_4);
	    //__HAL_TIM_SET_COMPARE(&htim2,TIM_CHANNEL_4,100);

		  //HAL_TIM_Base_Start_IT(&htim2);
			HAL_TIM_Base_Start(&htim3); // timer 3 doc ADC
		  HAL_TIM_Base_Start_IT(&htim4);
  /* USER CODE END 2 */

  /* Infinite loop */
  /* USER CODE BEGIN WHILE */
	t_show = HAL_GetTick();
  while (1)
  {

  /* USER CODE END WHILE */

  /* USER CODE BEGIN 3 */
		if(HAL_GetTick() - t_show > 40) //40ms se hien thi 1 lan ( 24)
		{
			      t_show = HAL_GetTick();
			      //resize_data();
						for(char x=0;x<64;x++)
						{
							 char y;
							 for(y=0;y<data_M[x]/2000;y++)
							 {
								 char temp = 31-y;
								 display[0][temp][x] = image[0][temp][x];
								 display[1][temp][x] = image[1][temp][x];
								 display[2][temp][x] = image[2][temp][x];
							 }
							 for(;y<32;y++)display[0][31-y][x]=display[1][31-y][x]=display[2][31-y][x]=0;
						}
						P5_display();
		}
	  if(TIM3 -> SR == 0x1F) // cho co ngat
		{
			TIM3 -> CNT = 0; //xoa bo dem CNT cho dem lai
			TIM3 -> SR=1; //xoa co

			  HAL_ADC_Start(&hadc1);  //doc du lieu ADC
			  HAL_ADC_PollForConversion(&hadc1,10000);
				RE[dem_ADC] =  (HAL_ADC_GetValue(&hadc1) - 2047); //to mid
				IM[dem_ADC] = 0;
			  dem_ADC++;
				if(dem_ADC>512) //neu da lay du N mau
			  {
				 dem_ADC=0;
				 //tinh FFT
				 FFT();
				 int y_y=0;
				 for (int i=1; i< 130;i++) // su dung tam 130/256 diem
					{
						RE[y_y] = sqrt(RE[i] * RE[i] + IM[i] * IM[i]);  // tinh Ak
						y_y++;
					}
				 save_data();
			  }
    }
  }
  /* USER CODE END 3 */

}

void SystemClock_Config(void)
{

  RCC_OscInitTypeDef RCC_OscInitStruct;
  RCC_ClkInitTypeDef RCC_ClkInitStruct;
  RCC_PeriphCLKInitTypeDef PeriphClkInit;

    /**Initializes the CPU, AHB and APB busses clocks
    */
  RCC_OscInitStruct.OscillatorType = RCC_OSCILLATORTYPE_HSE;
  RCC_OscInitStruct.HSEState = RCC_HSE_ON;
  RCC_OscInitStruct.HSEPredivValue = RCC_HSE_PREDIV_DIV1;
  RCC_OscInitStruct.HSIState = RCC_HSI_ON;
  RCC_OscInitStruct.PLL.PLLState = RCC_PLL_ON;
  RCC_OscInitStruct.PLL.PLLSource = RCC_PLLSOURCE_HSE;
  RCC_OscInitStruct.PLL.PLLMUL = RCC_PLL_MUL16;
  if (HAL_RCC_OscConfig(&RCC_OscInitStruct) != HAL_OK)
  {
    _Error_Handler(__FILE__, __LINE__);
  }

    /**Initializes the CPU, AHB and APB busses clocks
    */
  RCC_ClkInitStruct.ClockType = RCC_CLOCKTYPE_HCLK|RCC_CLOCKTYPE_SYSCLK
                              |RCC_CLOCKTYPE_PCLK1|RCC_CLOCKTYPE_PCLK2;
  RCC_ClkInitStruct.SYSCLKSource = RCC_SYSCLKSOURCE_PLLCLK;
  RCC_ClkInitStruct.AHBCLKDivider = RCC_SYSCLK_DIV1;
  RCC_ClkInitStruct.APB1CLKDivider = RCC_HCLK_DIV4;
  RCC_ClkInitStruct.APB2CLKDivider = RCC_HCLK_DIV4;

  if (HAL_RCC_ClockConfig(&RCC_ClkInitStruct, FLASH_LATENCY_2) != HAL_OK)
  {
    _Error_Handler(__FILE__, __LINE__);
  }

  PeriphClkInit.PeriphClockSelection = RCC_PERIPHCLK_ADC;
  PeriphClkInit.AdcClockSelection = RCC_ADCPCLK2_DIV4;
  if (HAL_RCCEx_PeriphCLKConfig(&PeriphClkInit) != HAL_OK)
  {
    _Error_Handler(__FILE__, __LINE__);
  }

    /**Configure the Systick interrupt time
    */
  HAL_SYSTICK_Config(HAL_RCC_GetHCLKFreq()/1000);

    /**Configure the Systick
    */
  HAL_SYSTICK_CLKSourceConfig(SYSTICK_CLKSOURCE_HCLK);

  /* SysTick_IRQn interrupt configuration */
  HAL_NVIC_SetPriority(SysTick_IRQn, 0, 0);
}

/* ADC1 init function */
static void MX_ADC1_Init(void)
{

  ADC_ChannelConfTypeDef sConfig;

    /**Common config
    */
  hadc1.Instance = ADC1;
  hadc1.Init.ScanConvMode = ADC_SCAN_DISABLE;
  hadc1.Init.ContinuousConvMode = DISABLE;
  hadc1.Init.DiscontinuousConvMode = DISABLE;
  hadc1.Init.ExternalTrigConv = ADC_SOFTWARE_START;
  hadc1.Init.DataAlign = ADC_DATAALIGN_RIGHT;
  hadc1.Init.NbrOfConversion = 1;
  if (HAL_ADC_Init(&hadc1) != HAL_OK)
  {
    _Error_Handler(__FILE__, __LINE__);
  }

    /**Configure Regular Channel
    */
  sConfig.Channel = ADC_CHANNEL_0;
  sConfig.Rank = ADC_REGULAR_RANK_1;
  sConfig.SamplingTime = ADC_SAMPLETIME_1CYCLE_5;
  if (HAL_ADC_ConfigChannel(&hadc1, &sConfig) != HAL_OK)
  {
    _Error_Handler(__FILE__, __LINE__);
  }

}

/* TIM2 init function */
static void MX_TIM2_Init(void)
{

  TIM_ClockConfigTypeDef sClockSourceConfig;
  TIM_MasterConfigTypeDef sMasterConfig;

  htim2.Instance = TIM2;
  htim2.Init.Prescaler = 32000;
  htim2.Init.CounterMode = TIM_COUNTERMODE_UP;
  htim2.Init.Period = 999;
  htim2.Init.ClockDivision = TIM_CLOCKDIVISION_DIV1;
  htim2.Init.AutoReloadPreload = TIM_AUTORELOAD_PRELOAD_DISABLE;
  if (HAL_TIM_Base_Init(&htim2) != HAL_OK)
  {
    _Error_Handler(__FILE__, __LINE__);
  }

  sClockSourceConfig.ClockSource = TIM_CLOCKSOURCE_INTERNAL;
  if (HAL_TIM_ConfigClockSource(&htim2, &sClockSourceConfig) != HAL_OK)
  {
    _Error_Handler(__FILE__, __LINE__);
  }

  sMasterConfig.MasterOutputTrigger = TIM_TRGO_RESET;
  sMasterConfig.MasterSlaveMode = TIM_MASTERSLAVEMODE_DISABLE;
  if (HAL_TIMEx_MasterConfigSynchronization(&htim2, &sMasterConfig) != HAL_OK)
  {
    _Error_Handler(__FILE__, __LINE__);
  }

}

/* TIM3 init function */
static void MX_TIM3_Init(void)
{

  TIM_ClockConfigTypeDef sClockSourceConfig;
  TIM_MasterConfigTypeDef sMasterConfig;

  htim3.Instance = TIM3;
  htim3.Init.Prescaler = 64;
  htim3.Init.CounterMode = TIM_COUNTERMODE_UP;
  htim3.Init.Period = 30;
  htim3.Init.ClockDivision = TIM_CLOCKDIVISION_DIV1;
  htim3.Init.AutoReloadPreload = TIM_AUTORELOAD_PRELOAD_DISABLE;
  if (HAL_TIM_Base_Init(&htim3) != HAL_OK)
  {
    _Error_Handler(__FILE__, __LINE__);
  }

  sClockSourceConfig.ClockSource = TIM_CLOCKSOURCE_INTERNAL;
  if (HAL_TIM_ConfigClockSource(&htim3, &sClockSourceConfig) != HAL_OK)
  {
    _Error_Handler(__FILE__, __LINE__);
  }

  sMasterConfig.MasterOutputTrigger = TIM_TRGO_RESET;
  sMasterConfig.MasterSlaveMode = TIM_MASTERSLAVEMODE_DISABLE;
  if (HAL_TIMEx_MasterConfigSynchronization(&htim3, &sMasterConfig) != HAL_OK)
  {
    _Error_Handler(__FILE__, __LINE__);
  }

}

/* TIM4 init function */
static void MX_TIM4_Init(void)
{

  TIM_ClockConfigTypeDef sClockSourceConfig;
  TIM_MasterConfigTypeDef sMasterConfig;

  htim4.Instance = TIM4;
  htim4.Init.Prescaler = 1152;
  htim4.Init.CounterMode = TIM_COUNTERMODE_UP;
  htim4.Init.Period = 33;
  htim4.Init.ClockDivision = TIM_CLOCKDIVISION_DIV1;
  htim4.Init.AutoReloadPreload = TIM_AUTORELOAD_PRELOAD_DISABLE;
  if (HAL_TIM_Base_Init(&htim4) != HAL_OK)
  {
    _Error_Handler(__FILE__, __LINE__);
  }

  sClockSourceConfig.ClockSource = TIM_CLOCKSOURCE_INTERNAL;
  if (HAL_TIM_ConfigClockSource(&htim4, &sClockSourceConfig) != HAL_OK)
  {
    _Error_Handler(__FILE__, __LINE__);
  }

  sMasterConfig.MasterOutputTrigger = TIM_TRGO_RESET;
  sMasterConfig.MasterSlaveMode = TIM_MASTERSLAVEMODE_DISABLE;
  if (HAL_TIMEx_MasterConfigSynchronization(&htim4, &sMasterConfig) != HAL_OK)
  {
    _Error_Handler(__FILE__, __LINE__);
  }

}

/** Configure pins as
        * Analog
        * Input
        * Output
        * EVENT_OUT
        * EXTI
*/
static void MX_GPIO_Init(void)
{

  GPIO_InitTypeDef GPIO_InitStruct;

  /* GPIO Ports Clock Enable */
  __HAL_RCC_GPIOD_CLK_ENABLE();
  __HAL_RCC_GPIOA_CLK_ENABLE();
  __HAL_RCC_GPIOB_CLK_ENABLE();

  /*Configure GPIO pin Output Level */
  HAL_GPIO_WritePin(GPIOA, GPIO_PIN_1|GPIO_PIN_2|GPIO_PIN_3|GPIO_PIN_4
                          |GPIO_PIN_5|GPIO_PIN_6|GPIO_PIN_7, GPIO_PIN_SET);

  /*Configure GPIO pin Output Level */
  HAL_GPIO_WritePin(GPIOB, GPIO_PIN_0|GPIO_PIN_1|GPIO_PIN_2|GPIO_PIN_10
                          |GPIO_PIN_11|GPIO_PIN_12|GPIO_PIN_13|GPIO_PIN_14, GPIO_PIN_SET);

  /*Configure GPIO pins : PA1 PA2 PA3 PA4
                           PA5 PA6 PA7 */
  GPIO_InitStruct.Pin = GPIO_PIN_1|GPIO_PIN_2|GPIO_PIN_3|GPIO_PIN_4
                          |GPIO_PIN_5|GPIO_PIN_6|GPIO_PIN_7;
  GPIO_InitStruct.Mode = GPIO_MODE_OUTPUT_PP;
  GPIO_InitStruct.Speed = GPIO_SPEED_FREQ_HIGH;
  HAL_GPIO_Init(GPIOA, &GPIO_InitStruct);

  /*Configure GPIO pins : PB0 PB1 PB2 PB10
                           PB11 PB12 PB13 PB14 */
  GPIO_InitStruct.Pin = GPIO_PIN_0|GPIO_PIN_1|GPIO_PIN_2|GPIO_PIN_10
                          |GPIO_PIN_11|GPIO_PIN_12|GPIO_PIN_13|GPIO_PIN_14;
  GPIO_InitStruct.Mode = GPIO_MODE_OUTPUT_PP;
  GPIO_InitStruct.Speed = GPIO_SPEED_FREQ_HIGH;
  HAL_GPIO_Init(GPIOB, &GPIO_InitStruct);

}

void _Error_Handler(char *file, int line)
{
  while(1)
  {
  }
}

/************************ (C) COPYRIGHT STMicroelectronics *****END OF FILE****/
